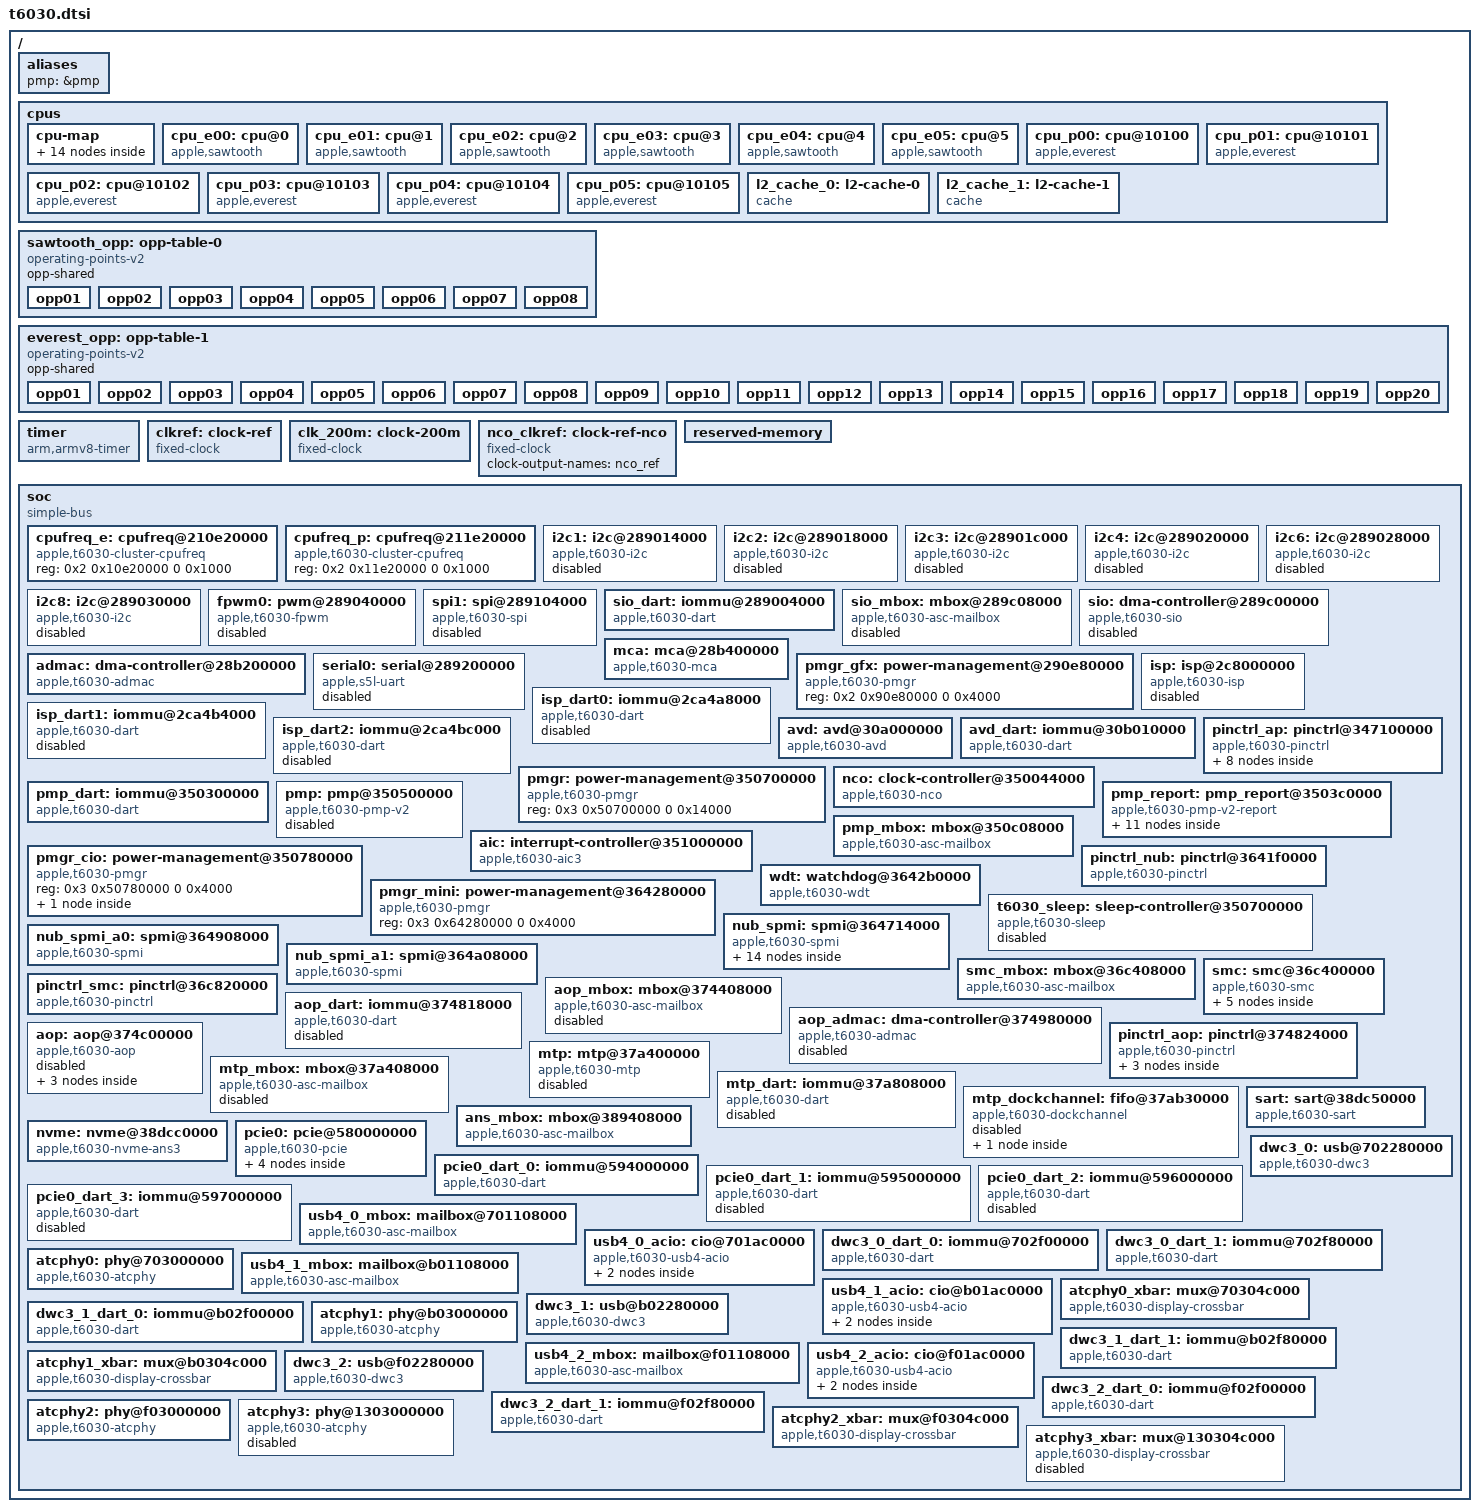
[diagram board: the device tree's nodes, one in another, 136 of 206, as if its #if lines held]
// SPDX-License-Identifier: GPL-2.0+ OR MIT
/*
 * Apple T6030 "M3 Pro" SoC
 *
 * Other names: H15J, "Lobos"
 *
 * Copyright The Asahi Linux Contributors
 */

#include <dt-bindings/gpio/gpio.h>
#include <dt-bindings/interrupt-controller/apple-aic.h>
#include <dt-bindings/interrupt-controller/irq.h>
#include <dt-bindings/pinctrl/apple.h>
#include <dt-bindings/phy/phy.h>
#include <dt-bindings/spmi/spmi.h>

/ {
	#address-cells = <2>;
	#size-cells = <2>;

	aliases {
		#ifdef APPLE_USE_PMP
		pmp = &pmp;
		#endif
	};

	cpus {
		#address-cells = <2>;
		#size-cells = <0>;

		cpu-map {
			cluster0 {
				core0 {
					cpu = <&cpu_e00>;
				};
				core1 {
					cpu = <&cpu_e01>;
				};
				core2 {
					cpu = <&cpu_e02>;
				};
				core3 {
					cpu = <&cpu_e03>;
				};
				core4 {
					cpu = <&cpu_e04>;
				};
				core5 {
					cpu = <&cpu_e05>;
				};
			};

			cluster1 {
				core0 {
					cpu = <&cpu_p00>;
				};
				core1 {
					cpu = <&cpu_p01>;
				};
				core2 {
					cpu = <&cpu_p02>;
				};
				core3 {
					cpu = <&cpu_p03>;
				};
				core4 {
					cpu = <&cpu_p04>;
				};
				core5 {
					cpu = <&cpu_p05>;
				};
			};
		};

		cpu_e00: cpu@0 {
			compatible = "apple,sawtooth";
			device_type = "cpu";
			reg = <0x0 0x0>;
			enable-method = "spin-table";
			cpu-release-addr = <0 0>; /* to be filled by loader */
			next-level-cache = <&l2_cache_0>;
			i-cache-size = <0x20000>;
			d-cache-size = <0x10000>;
			operating-points-v2 = <&sawtooth_opp>;
			capacity-dmips-mhz = <851>;
			performance-domains = <&cpufreq_e>;
		};

		cpu_e01: cpu@1 {
			compatible = "apple,sawtooth";
			device_type = "cpu";
			reg = <0x0 0x1>;
			enable-method = "spin-table";
			cpu-release-addr = <0 0>; /* to be filled by loader */
			next-level-cache = <&l2_cache_0>;
			i-cache-size = <0x20000>;
			d-cache-size = <0x10000>;
			operating-points-v2 = <&sawtooth_opp>;
			capacity-dmips-mhz = <851>;
			performance-domains = <&cpufreq_e>;
		};

		cpu_e02: cpu@2 {
			compatible = "apple,sawtooth";
			device_type = "cpu";
			reg = <0x0 0x2>;
			enable-method = "spin-table";
			cpu-release-addr = <0 0>; /* to be filled by loader */
			next-level-cache = <&l2_cache_0>;
			i-cache-size = <0x20000>;
			d-cache-size = <0x10000>;
			operating-points-v2 = <&sawtooth_opp>;
			capacity-dmips-mhz = <851>;
			performance-domains = <&cpufreq_e>;
		};

		cpu_e03: cpu@3 {
			compatible = "apple,sawtooth";
			device_type = "cpu";
			reg = <0x0 0x3>;
			enable-method = "spin-table";
			cpu-release-addr = <0 0>; /* to be filled by loader */
			next-level-cache = <&l2_cache_0>;
			i-cache-size = <0x20000>;
			d-cache-size = <0x10000>;
			operating-points-v2 = <&sawtooth_opp>;
			capacity-dmips-mhz = <851>;
			performance-domains = <&cpufreq_e>;
		};

		cpu_e04: cpu@4 {
			compatible = "apple,sawtooth";
			device_type = "cpu";
			reg = <0x0 0x4>;
			enable-method = "spin-table";
			cpu-release-addr = <0 0>; /* to be filled by loader */
			next-level-cache = <&l2_cache_0>;
			i-cache-size = <0x20000>;
			d-cache-size = <0x10000>;
			operating-points-v2 = <&sawtooth_opp>;
			capacity-dmips-mhz = <851>;
			performance-domains = <&cpufreq_e>;
		};

		cpu_e05: cpu@5 {
			compatible = "apple,sawtooth";
			device_type = "cpu";
			reg = <0x0 0x5>;
			enable-method = "spin-table";
			cpu-release-addr = <0 0>; /* to be filled by loader */
			next-level-cache = <&l2_cache_0>;
			i-cache-size = <0x20000>;
			d-cache-size = <0x10000>;
			operating-points-v2 = <&sawtooth_opp>;
			capacity-dmips-mhz = <851>;
			performance-domains = <&cpufreq_e>;
		};

		cpu_p00: cpu@10100 {
			compatible = "apple,everest";
			device_type = "cpu";
			reg = <0x0 0x10100>;
			enable-method = "spin-table";
			cpu-release-addr = <0 0>; /* To be filled by loader */
			next-level-cache = <&l2_cache_1>;
			i-cache-size = <0x30000>;
			d-cache-size = <0x20000>;
			operating-points-v2 = <&everest_opp>;
			capacity-dmips-mhz = <1024>;
			performance-domains = <&cpufreq_p>;
		};

		cpu_p01: cpu@10101 {
			compatible = "apple,everest";
			device_type = "cpu";
			reg = <0x0 0x10101>;
			enable-method = "spin-table";
			cpu-release-addr = <0 0>; /* To be filled by loader */
			next-level-cache = <&l2_cache_1>;
			i-cache-size = <0x30000>;
			d-cache-size = <0x20000>;
			operating-points-v2 = <&everest_opp>;
			capacity-dmips-mhz = <1024>;
			performance-domains = <&cpufreq_p>;
		};

		cpu_p02: cpu@10102 {
			compatible = "apple,everest";
			device_type = "cpu";
			reg = <0x0 0x10102>;
			enable-method = "spin-table";
			cpu-release-addr = <0 0>; /* To be filled by loader */
			next-level-cache = <&l2_cache_1>;
			i-cache-size = <0x30000>;
			d-cache-size = <0x20000>;
			operating-points-v2 = <&everest_opp>;
			capacity-dmips-mhz = <1024>;
			performance-domains = <&cpufreq_p>;
		};

		cpu_p03: cpu@10103 {
			compatible = "apple,everest";
			device_type = "cpu";
			reg = <0x0 0x10103>;
			enable-method = "spin-table";
			cpu-release-addr = <0 0>; /* To be filled by loader */
			next-level-cache = <&l2_cache_1>;
			i-cache-size = <0x30000>;
			d-cache-size = <0x20000>;
			operating-points-v2 = <&everest_opp>;
			capacity-dmips-mhz = <1024>;
			performance-domains = <&cpufreq_p>;
		};

		cpu_p04: cpu@10104 {
			compatible = "apple,everest";
			device_type = "cpu";
			reg = <0x0 0x10104>;
			enable-method = "spin-table";
			cpu-release-addr = <0 0>; /* To be filled by loader */
			next-level-cache = <&l2_cache_1>;
			i-cache-size = <0x30000>;
			d-cache-size = <0x20000>;
			operating-points-v2 = <&everest_opp>;
			capacity-dmips-mhz = <1024>;
			performance-domains = <&cpufreq_p>;
		};

		cpu_p05: cpu@10105 {
			compatible = "apple,everest";
			device_type = "cpu";
			reg = <0x0 0x10105>;
			enable-method = "spin-table";
			cpu-release-addr = <0 0>; /* To be filled by loader */
			next-level-cache = <&l2_cache_1>;
			i-cache-size = <0x30000>;
			d-cache-size = <0x20000>;
			operating-points-v2 = <&everest_opp>;
			capacity-dmips-mhz = <1024>;
			performance-domains = <&cpufreq_p>;
		};

		l2_cache_0: l2-cache-0 {
			compatible = "cache";
			cache-level = <2>;
			cache-unified;
			cache-size = <0x400000>;
		};

		l2_cache_1: l2-cache-1 {
			compatible = "cache";
			cache-level = <2>;
			cache-unified;
			cache-size = <0x1000000>;
		};
	};

	sawtooth_opp: opp-table-0 {
		compatible = "operating-points-v2";
		opp-shared;

		opp01 {
			opp-hz = /bits/ 64 <744000000>;
			opp-level = <1>;
			clock-latency-ns = <7700>;
		};
		opp02 {
			opp-hz = /bits/ 64 <1044000000>;
			opp-level = <2>;
			clock-latency-ns = <21200>;
		};
		opp03 {
			opp-hz = /bits/ 64 <1476000000>;
			opp-level = <3>;
			clock-latency-ns = <26400>;
		};
		opp04 {
			opp-hz = /bits/ 64 <2004000000>;
			opp-level = <4>;
			clock-latency-ns = <40500>;
		};
		opp05 {
			opp-hz = /bits/ 64 <2268000000>;
			opp-level = <5>;
			clock-latency-ns = <44400>;
		};
		opp06 {
			opp-hz = /bits/ 64 <2448000000>;
			opp-level = <6>;
			clock-latency-ns = <47200>;
		};
		opp07 {
			opp-hz = /bits/ 64 <2640000000>;
			opp-level = <7>;
			clock-latency-ns = <52000>;
		};
		opp08 {
			opp-hz = /bits/ 64 <2748000000>;
			opp-level = <8>;
			clock-latency-ns = <52000>;
		};
	};

	everest_opp: opp-table-1 {
		compatible = "operating-points-v2";
		opp-shared;

		opp01 {
			opp-hz = /bits/ 64 <696000000>;
			opp-level = <1>;
			clock-latency-ns = <8600>;
		};
		opp02 {
			opp-hz = /bits/ 64 <1092000000>;
			opp-level = <2>;
			clock-latency-ns = <18700>;
		};
		opp03 {
			opp-hz = /bits/ 64 <1356000000>;
			opp-level = <3>;
			clock-latency-ns = <20700>;
		};
		opp04 {
			opp-hz = /bits/ 64 <1596000000>;
			opp-level = <4>;
			clock-latency-ns = <24800>;
		};
		opp05 {
			opp-hz = /bits/ 64 <1884000000>;
			opp-level = <5>;
			clock-latency-ns = <30700>;
		};
		opp06 {
			opp-hz = /bits/ 64 <2172000000>;
			opp-level = <6>;
			clock-latency-ns = <34400>;
		};
		opp07 {
			opp-hz = /bits/ 64 <2424000000>;
			opp-level = <7>;
			clock-latency-ns = <39600>;
		};
		opp08 {
			opp-hz = /bits/ 64 <2616000000>;
			opp-level = <8>;
			clock-latency-ns = <40000>;
		};
		opp09 {
			opp-hz = /bits/ 64 <2808000000>;
			opp-level = <9>;
			clock-latency-ns = <41800>;
		};
		opp10 {
			opp-hz = /bits/ 64 <2988000000>;
			opp-level = <10>;
			clock-latency-ns = <45300>;
		};
		opp11 {
			opp-hz = /bits/ 64 <3144000000>;
			opp-level = <11>;
			clock-latency-ns = <46700>;
		};
		opp12 {
			opp-hz = /bits/ 64 <3288000000>;
			opp-level = <12>;
			clock-latency-ns = <49200>;
		};
		opp13 {
			opp-hz = /bits/ 64 <3420000000>;
			opp-level = <13>;
			clock-latency-ns = <53900>;
		};
		opp14 {
			opp-hz = /bits/ 64 <3576000000>;
			opp-level = <14>;
			clock-latency-ns = <53700>;
		};
		opp15 {
			opp-hz = /bits/ 64 <3624000000>;
			opp-level = <15>;
			clock-latency-ns = <54000>;
		};
		opp16 {
			opp-hz = /bits/ 64 <3708000000>;
			opp-level = <16>;
			clock-latency-ns = <54000>;
		};
		opp17 {
			opp-hz = /bits/ 64 <3780000000>;
			opp-level = <17>;
			clock-latency-ns = <54100>;
		};
		opp18 {
			opp-hz = /bits/ 64 <3864000000>;
			opp-level = <18>;
			clock-latency-ns = <54300>;
		};
		opp19 {
			opp-hz = /bits/ 64 <3960000000>;
			opp-level = <19>;
			clock-latency-ns = <58400>;
		};
		opp20 {
			opp-hz = /bits/ 64 <4056000000>;
			opp-level = <20>;
			clock-latency-ns = <58700>;
		};
	};

	timer {
		compatible = "arm,armv8-timer";
		interrupt-parent = <&aic>;
		interrupt-names = "phys", "virt", "hyp-phys", "hyp-virt";
		interrupts = <AIC_FIQ AIC_TMR_GUEST_PHYS IRQ_TYPE_LEVEL_HIGH>,
			     <AIC_FIQ AIC_TMR_GUEST_VIRT IRQ_TYPE_LEVEL_HIGH>,
			     <AIC_FIQ AIC_TMR_HV_PHYS IRQ_TYPE_LEVEL_HIGH>,
			     <AIC_FIQ AIC_TMR_HV_VIRT IRQ_TYPE_LEVEL_HIGH>;
	};

	clkref: clock-ref {
		compatible = "fixed-clock";
		#clock-cells = <0>;
		clock-frequency = <24000000>;
		clock-output-names = "clkref";
	};

	clk_200m: clock-200m {
		compatible = "fixed-clock";
		#clock-cells = <0>;
		clock-frequency = <200000000>;
		clock-output-names = "clk_200m";
	};

	/*
	 * This is a fabulated representation of the input clock
	 * to NCO since we don't know the true clock tree.
	 */
	nco_clkref: clock-ref-nco {
		compatible = "fixed-clock";
		#clock-cells = <0>;
		clock-output-names = "nco_ref";
	};

	reserved-memory {
		#address-cells = <2>;
		#size-cells = <2>;
		ranges;
	};

	soc: soc {
		compatible = "simple-bus";
		#address-cells = <2>;
		#size-cells = <2>;

		ranges;
		nonposted-mmio;
		/* Required to get >32-bit DMA via DARTs */
		dma-ranges = <0 0 0 0 0xffffffff 0xffffc000>;

		cpufreq_e: cpufreq@210e20000 {
			compatible = "apple,t6030-cluster-cpufreq", "apple,t8112-cluster-cpufreq";
			reg = <0x2 0x10e20000 0 0x1000>;
			#performance-domain-cells = <0>;
		};

		cpufreq_p: cpufreq@211e20000 {
			compatible = "apple,t6030-cluster-cpufreq", "apple,t8112-cluster-cpufreq";
			reg = <0x2 0x11e20000 0 0x1000>;
			#performance-domain-cells = <0>;
		};

		i2c1: i2c@289014000 {
			compatible = "apple,t6030-i2c", "apple,t8103-i2c";
			reg = <0x2 0x89014000 0x0 0x4000>;
			clocks = <&clkref>;
			interrupt-parent = <&aic>;
			interrupts = <AIC_IRQ 890 IRQ_TYPE_LEVEL_HIGH>;
			pinctrl-0 = <&i2c1_pins>;
			pinctrl-names = "default";
			#address-cells = <0x1>;
			#size-cells = <0x0>;
			power-domains = <&ps_i2c1>;
			status = "disabled";
		};

		i2c2: i2c@289018000 {
			compatible = "apple,t6030-i2c", "apple,t8103-i2c";
			reg = <0x2 0x89018000 0x0 0x4000>;
			clocks = <&clkref>;
			interrupt-parent = <&aic>;
			interrupts = <AIC_IRQ 891 IRQ_TYPE_LEVEL_HIGH>;
			pinctrl-0 = <&i2c2_pins>;
			pinctrl-names = "default";
			#address-cells = <0x1>;
			#size-cells = <0x0>;
			power-domains = <&ps_i2c2>;
			status = "disabled";
		};

		i2c3: i2c@28901c000 {
			compatible = "apple,t6030-i2c", "apple,t8103-i2c";
			reg = <0x2 0x8901c000 0x0 0x4000>;
			clocks = <&clkref>;
			interrupt-parent = <&aic>;
			interrupts = <AIC_IRQ 892 IRQ_TYPE_LEVEL_HIGH>;
			pinctrl-0 = <&i2c3_pins>;
			pinctrl-names = "default";
			#address-cells = <0x1>;
			#size-cells = <0x0>;
			power-domains = <&ps_i2c3>;
			status = "disabled";
		};

		i2c4: i2c@289020000 {
			compatible = "apple,t6030-i2c", "apple,t8103-i2c";
			reg = <0x2 0x89020000 0x0 0x4000>;
			clocks = <&clkref>;
			interrupt-parent = <&aic>;
			interrupts = <AIC_IRQ 893 IRQ_TYPE_LEVEL_HIGH>;
			pinctrl-0 = <&i2c4_pins>;
			pinctrl-names = "default";
			#address-cells = <0x1>;
			#size-cells = <0x0>;
			power-domains = <&ps_i2c4>;
			status = "disabled";
		};

		i2c6: i2c@289028000 {
			compatible = "apple,t6030-i2c", "apple,t8103-i2c";
			reg = <0x2 0x89028000 0x0 0x4000>;
			clocks = <&clkref>;
			interrupt-parent = <&aic>;
			interrupts = <AIC_IRQ 895 IRQ_TYPE_LEVEL_HIGH>;
			pinctrl-0 = <&i2c6_pins>;
			pinctrl-names = "default";
			#address-cells = <0x1>;
			#size-cells = <0x0>;
			power-domains = <&ps_i2c6>;
			status = "disabled";
		};

		i2c8: i2c@289030000 {
			compatible = "apple,t6030-i2c", "apple,t8103-i2c";
			reg = <0x2 0x89030000 0x0 0x4000>;
			clocks = <&clkref>;
			interrupt-parent = <&aic>;
			interrupts = <AIC_IRQ 897 IRQ_TYPE_LEVEL_HIGH>;
			pinctrl-0 = <&i2c8_pins>;
			pinctrl-names = "default";
			#address-cells = <0x1>;
			#size-cells = <0x0>;
			power-domains = <&ps_i2c8>;
			status = "disabled";
		};

		fpwm0: pwm@289040000 {
			compatible = "apple,t6030-fpwm", "apple,s5l-fpwm";
			reg = <0x2 0x89040000 0x0 0x4000>;
			power-domains = <&ps_fpwm0>;
			clocks = <&clkref>;
			#pwm-cells = <2>;
			status = "disabled";
		};

		spi1: spi@289104000 {
			compatible = "apple,t6030-spi", "apple,t8103-spi";
			reg = <0x2 0x89104000 0x0 0x4000>;
			interrupt-parent = <&aic>;
			interrupts = <AIC_IRQ 875 IRQ_TYPE_LEVEL_HIGH>;
			#address-cells = <1>;
			#size-cells = <0>;
			clocks = <&clk_200m>;
			pinctrl-0 = <&spi1_pins>;
			pinctrl-names = "default";
			power-domains = <&ps_spi1>;
			status = "disabled";
		};

		sio_dart: iommu@289004000 {
			compatible = "apple,t6030-dart", "apple,t8110-dart";
			reg = <0x2 0x89004000 0x0 0x4000>;
			interrupt-parent = <&aic>;
			interrupts = <AIC_IRQ 901 IRQ_TYPE_LEVEL_HIGH>;
			#iommu-cells = <1>;
			power-domains = <&ps_sio>;
		};

		sio_mbox: mbox@289c08000 {
			compatible = "apple,t6030-asc-mailbox", "apple,asc-mailbox-v4";
			reg = <0x2 0x89c08000 0x0 0x4000>;
			interrupt-parent = <&aic>;
			interrupts = <AIC_IRQ 907 IRQ_TYPE_LEVEL_HIGH>,
				<AIC_IRQ 908 IRQ_TYPE_LEVEL_HIGH>,
				<AIC_IRQ 909 IRQ_TYPE_LEVEL_HIGH>,
				<AIC_IRQ 910 IRQ_TYPE_LEVEL_HIGH>;
			interrupt-names = "send-empty", "send-not-empty",
				"recv-empty", "recv-not-empty";
			#mbox-cells = <0>;
			power-domains = <&ps_sio_cpu>;
			status = "disabled";
		};

		/* Enabled by the boot loader with its firmware and parameters. */
		sio: dma-controller@289c00000 {
			compatible = "apple,t6030-sio", "apple,sio";
			reg = <0x2 0x89c00000 0x0 0x8000>;
			dma-channels = <128>;
			#dma-cells = <1>;
			mboxes = <&sio_mbox>;
			iommus = <&sio_dart 0>;
			power-domains = <&ps_sio_cpu>;
			status = "disabled";
		};

		admac: dma-controller@28b200000 {
			compatible = "apple,t6030-admac", "apple,t8122-admac";
			reg = <0x2 0x8b200000 0x0 0x34000>;
			#dma-cells = <1>;
			dma-channels = <24>;
			interrupts-extended = <0>,
					      <&aic AIC_IRQ 888 IRQ_TYPE_LEVEL_HIGH>,
					      <0>,
					      <0>;
			iommus = <&sio_dart 2>;
			power-domains = <&ps_sio_adma>;
			resets = <&ps_audio_p>;
		};

		mca: mca@28b400000 {
			compatible = "apple,t6030-mca", "apple,t8103-mca";
			reg = <0x2 0x8b400000 0x0 0x10000>,
			      <0x2 0x8b300000 0x0 0x20000>;
			clocks = <&nco 0>, <&nco 1>, <&nco 2>, <&nco 3>;
			dmas = <&admac 0>, <&admac 1>, <&admac 2>, <&admac 3>,
			       <&admac 4>, <&admac 5>, <&admac 6>, <&admac 7>,
			       <&admac 8>, <&admac 9>, <&admac 10>, <&admac 11>,
			       <&admac 12>, <&admac 13>, <&admac 14>, <&admac 15>;
			dma-names = "tx0a", "rx0a", "tx0b", "rx0b",
				    "tx1a", "rx1a", "tx1b", "rx1b",
				    "tx2a", "rx2a", "tx2b", "rx2b",
				    "tx3a", "rx3a", "tx3b", "rx3b";
			interrupt-parent = <&aic>;
			interrupts = <AIC_IRQ 881 IRQ_TYPE_LEVEL_HIGH>,
				     <AIC_IRQ 882 IRQ_TYPE_LEVEL_HIGH>,
				     <AIC_IRQ 883 IRQ_TYPE_LEVEL_HIGH>,
				     <AIC_IRQ 884 IRQ_TYPE_LEVEL_HIGH>;
			power-domains = <&ps_audio_p>, <&ps_mca0>, <&ps_mca1>,
					<&ps_mca2>, <&ps_mca3>;
			resets = <&ps_audio_p>;
			#sound-dai-cells = <1>;
		};

		serial0: serial@289200000 {
			compatible = "apple,s5l-uart";
			reg = <0x2 0x89200000 0x0 0x1000>;
			reg-io-width = <4>;
			interrupt-parent = <&aic>;
			interrupts = <AIC_IRQ 866 IRQ_TYPE_LEVEL_HIGH>;
			/*
			 * TODO: figure out the clocking properly, there may
			 * be a third selectable clock.
			 */
			clocks = <&clkref>, <&clkref>;
			clock-names = "uart", "clk_uart_baud0";
			power-domains = <&ps_uart0>;
			status = "disabled";
		};

		pmgr_gfx: power-management@290e80000 {
			compatible = "apple,t6030-pmgr", "apple,t8103-pmgr", "syscon", "simple-mfd";
			#address-cells = <1>;
			#size-cells = <1>;

			reg = <0x2 0x90e80000 0 0x4000>;
			/* child nodes are added in t6030-pmgr.dtsi */
		};

		isp: isp@2c8000000 {
			compatible = "apple,t6030-isp";
			iommus = <&isp_dart0 0>, <&isp_dart1 0>, <&isp_dart2 0>;
			reg-names = "coproc", "mbox", "gpio", "mbox2";
			reg = <0x2 0xc8000000 0x0 0x2000000>,
				<0x2 0xca4c4000 0x0 0x100>,
				<0x2 0xca4c41d0 0x0 0x100>,
				<0x2 0xca4c4458 0x0 0x100>;
			interrupt-parent = <&aic>;
			interrupts = <AIC_IRQ 359 IRQ_TYPE_LEVEL_HIGH>;
			power-domains = <&ps_isp_sys>, <&ps_ispsens0>,
				<&ps_isp_cpu>, <&ps_isp_fe>, <&ps_dprx>,
				<&ps_isp_secure>, <&ps_isp_be>, <&ps_isp_clr>;
			apple,dart-vm-size = <0x0 0xa0000000>;

			status = "disabled";
		};

		isp_dart0: iommu@2ca4a8000 {
			compatible = "apple,t6030-dart", "apple,t8110-dart";
			reg = <0x2 0xca4a8000 0x0 0x4000>;
			#iommu-cells = <1>;
			interrupt-parent = <&aic>;
			interrupts = <AIC_IRQ 364 IRQ_TYPE_LEVEL_HIGH>;
			power-domains = <&ps_isp_sys>;
			status = "disabled";
		};

		isp_dart1: iommu@2ca4b4000 {
			compatible = "apple,t6030-dart", "apple,t8110-dart";
			reg = <0x2 0xca4b4000 0x0 0x4000>;
			#iommu-cells = <1>;
			interrupt-parent = <&aic>;
			interrupts = <AIC_IRQ 364 IRQ_TYPE_LEVEL_HIGH>;
			power-domains = <&ps_isp_sys>;
			status = "disabled";
		};

		isp_dart2: iommu@2ca4bc000 {
			compatible = "apple,t6030-dart", "apple,t8110-dart";
			reg = <0x2 0xca4bc000 0x0 0x4000>;
			#iommu-cells = <1>;
			interrupt-parent = <&aic>;
			interrupts = <AIC_IRQ 364 IRQ_TYPE_LEVEL_HIGH>;
			power-domains = <&ps_isp_sys>;
			status = "disabled";
		};

		avd: avd@30a000000 {
			compatible = "apple,t6030-avd", "apple,t8122-avd";
			interrupt-parent = <&aic>;
			interrupts = <AIC_IRQ 788 IRQ_TYPE_LEVEL_HIGH>,
				<AIC_IRQ 789 IRQ_TYPE_LEVEL_HIGH>;
			#if defined(APPLE_USE_PMP)
			power-domains = <&pmp_report_avd_sys>;
			#else
			power-domains = <&ps_avd_sys>;
			#endif
			resets = <&ps_avd_sys>;
			reg = <0x3 0x0b080000 0x0 0x12000>,
				<0x3 0x0b092000 0x0 0x12000>,
				<0x3 0x0b0a4000 0x0 0x4000>,
				<0x3 0x0b100000 0x0 0x10000>;
			reg-names = "code", "sram", "mbox", "ctrl";
			iommus = <&avd_dart 0>;
		};

		avd_dart: iommu@30b010000 {
			compatible = "apple,t6030-dart", "apple,t8110-dart";
			reg = <0x3 0x0b010000 0x0 0x4000>;
			#iommu-cells = <1>;
			interrupt-parent = <&aic>;
			interrupts = <AIC_IRQ 795 IRQ_TYPE_LEVEL_HIGH>;
			power-domains = <&ps_avd_sys>;
		};

		pinctrl_ap: pinctrl@347100000 {
			compatible = "apple,t6030-pinctrl", "apple,t8103-pinctrl";
			reg = <0x3 0x47100000 0x0 0x4000>;

			interrupt-parent = <&aic>;
			interrupts = <AIC_IRQ 273 IRQ_TYPE_LEVEL_HIGH>,
				     <AIC_IRQ 274 IRQ_TYPE_LEVEL_HIGH>,
				     <AIC_IRQ 275 IRQ_TYPE_LEVEL_HIGH>,
				     <AIC_IRQ 276 IRQ_TYPE_LEVEL_HIGH>,
				     <AIC_IRQ 277 IRQ_TYPE_LEVEL_HIGH>,
				     <AIC_IRQ 278 IRQ_TYPE_LEVEL_HIGH>,
				     <AIC_IRQ 279 IRQ_TYPE_LEVEL_HIGH>;

			power-domains = <&ps_gpio>;

			gpio-controller;
			#gpio-cells = <2>;
			gpio-ranges = <&pinctrl_ap 0 0 224>;
			apple,npins = <224>;

			interrupt-controller;
			#interrupt-cells = <2>;

			i2c1_pins: i2c1-pins {
				pinmux = <APPLE_PINMUX(37, 1)>,
					 <APPLE_PINMUX(36, 1)>;
			};

			i2c2_pins: i2c2-pins {
				pinmux = <APPLE_PINMUX(43, 1)>,
					 <APPLE_PINMUX(42, 1)>;
			};

			i2c3_pins: i2c3-pins {
				pinmux = <APPLE_PINMUX(41, 1)>,
					 <APPLE_PINMUX(40, 1)>;
			};

			i2c4_pins: i2c4-pins {
				pinmux = <APPLE_PINMUX(39, 1)>,
					 <APPLE_PINMUX(38, 1)>;
			};

			i2c6_pins: i2c6-pins {
				pinmux = <APPLE_PINMUX(47, 1)>,
					 <APPLE_PINMUX(46, 1)>;
			};

			i2c8_pins: i2c8-pins {
				pinmux = <APPLE_PINMUX(51, 1)>,
					 <APPLE_PINMUX(50, 1)>;
			};

			spi1_pins: spi1-pins {
				pinmux = <APPLE_PINMUX(24, 1)>, /* SDI */
					<APPLE_PINMUX(25, 1)>,  /* SDO */
					<APPLE_PINMUX(26, 1)>,  /* SCK */
					<APPLE_PINMUX(27, 1)>;  /* CS */
			};

			pcie_pins: pcie-pins {
				// clkreq pins
				pinmux = <APPLE_PINMUX(163, 1)>,
					 <APPLE_PINMUX(164, 1)>,
					 <APPLE_PINMUX(165, 1)>,
					 <APPLE_PINMUX(166, 1)>;
			};
		};

		pmgr: power-management@350700000 {
			compatible = "apple,t6030-pmgr", "apple,t8103-pmgr", "syscon", "simple-mfd";
			#address-cells = <1>;
			#size-cells = <1>;

			reg = <0x3 0x50700000 0 0x14000>;
			/* child nodes are added in t6030-pmgr.dtsi */
		};

		nco: clock-controller@350044000 {
			compatible = "apple,t6030-nco", "apple,t8103-nco";
			reg = <0x3 0x50044000 0x0 0x14000>;
			clocks = <&nco_clkref>;
			#clock-cells = <1>;
		};

		/* The display handoff gate installs PMP unless explicitly static. */
		#ifdef APPLE_USE_PMP
		pmp_dart: iommu@350300000 {
			compatible = "apple,t6030-dart", "apple,t8110-dart";
			reg = <0x3 0x50300000 0x0 0x4000>;
			#iommu-cells = <1>;
			interrupt-parent = <&aic>;
			interrupts = <AIC_IRQ 734 IRQ_TYPE_LEVEL_HIGH>;
			power-domains = <&ps_pmp>;
		};

		pmp_report: pmp_report@3503c0000 {
			compatible = "apple,t6030-pmp-v2-report";
			reg = <0x3 0x503c0000 0x0 0x20000>;
			power-domains = <&ps_pms_sram>;
			#address-cells = <1>;
			#size-cells = <0>;

			pmp_report_ane_sys: report@5 {
				compatible = "apple,t6030-pmp-v2-report-entry",
					     "apple,t6000-pmp-v2-report-entry";
				reg = <0x5>;
				label = "pmp-ane-sys";
				#power-domain-cells = <0>;
				power-domains = <&ps_ane_sys>;
				status = "disabled";
			};

			pmp_report_isp_sys: report@6 {
				compatible = "apple,t6030-pmp-v2-report-entry",
					     "apple,t6000-pmp-v2-report-entry";
				reg = <0x6>;
				label = "pmp-isp-sys";
				#power-domain-cells = <0>;
				power-domains = <&ps_isp_sys>;
				status = "disabled";
			};

			pmp_report_disp: report@7 {
				compatible = "apple,t6030-pmp-v2-report-entry",
					     "apple,t6000-pmp-v2-report-entry";
				reg = <0x7>;
				label = "pmp-disp";
				#power-domain-cells = <0>;
				power-domains = <&ps_disp_cpu>;
				apple,always-on;
			};

			pmp_report_dispext0: report@8 {
				compatible = "apple,t6030-pmp-v2-report-entry",
					     "apple,t6000-pmp-v2-report-entry";
				reg = <0x8>;
				label = "pmp-dispext0";
				#power-domain-cells = <0>;
				power-domains = <&ps_dispext0_cpu>;
			};

			pmp_report_dispext1: report@9 {
				compatible = "apple,t6030-pmp-v2-report-entry",
					     "apple,t6000-pmp-v2-report-entry";
				reg = <0x9>;
				label = "pmp-dispext1";
				#power-domain-cells = <0>;
				power-domains = <&ps_dispext1_cpu>;
			};

			pmp_report_venc_sys: report@a {
				compatible = "apple,t6030-pmp-v2-report-entry",
					     "apple,t6000-pmp-v2-report-entry";
				reg = <0xa>;
				label = "pmp-venc-sys";
				#power-domain-cells = <0>;
				power-domains = <&ps_venc_sys>;
				status = "disabled";
			};

			pmp_report_avd_sys: report@b {
				compatible = "apple,t6030-pmp-v2-report-entry",
					     "apple,t6000-pmp-v2-report-entry";
				reg = <0xb>;
				label = "pmp-avd-sys";
				#power-domain-cells = <0>;
				power-domains = <&ps_avd_sys>;
			};

			pmp_report_msr: report@c {
				compatible = "apple,t6030-pmp-v2-report-entry",
					     "apple,t6000-pmp-v2-report-entry";
				reg = <0xc>;
				label = "pmp-msr";
				#power-domain-cells = <0>;
				power-domains = <&ps_msr>;
				status = "disabled";
			};

			pmp_report_jpg: report@d {
				compatible = "apple,t6030-pmp-v2-report-entry",
					     "apple,t6000-pmp-v2-report-entry";
				reg = <0xd>;
				label = "pmp-jpg";
				#power-domain-cells = <0>;
				power-domains = <&ps_jpg>;
				status = "disabled";
			};

			pmp_report_scodec: report@e {
				compatible = "apple,t6030-pmp-v2-report-entry",
					     "apple,t6000-pmp-v2-report-entry";
				reg = <0xe>;
				label = "pmp-scodec";
				#power-domain-cells = <0>;
				power-domains = <&ps_scodec>;
				status = "disabled";
			};

			pmp_report_ans: report@10 {
				compatible = "apple,t6030-pmp-v2-report-entry",
					     "apple,t6000-pmp-v2-report-entry";
				reg = <0x10>;
				label = "pmp-ans";
				#power-domain-cells = <0>;
				power-domains = <&ps_ans>;
			};
		};

		pmp: pmp@350500000 {
			compatible = "apple,t6030-pmp-v2", "apple,t6000-pmp-v2";
			reg = <0x3 0x50500000 0x0 0x80000>,
			      <0x3 0x50c00000 0x0 0x4000>;
			reg-names = "pmp", "asc";
			mboxes = <&pmp_mbox>;
			mbox-names = "mbox";
			iommus = <&pmp_dart 0>;
			power-domains = <&ps_pmp>;
			status = "disabled";
		};

		pmp_mbox: mbox@350c08000 {
			compatible = "apple,t6030-asc-mailbox", "apple,asc-mailbox-v4";
			reg = <0x3 0x50c08000 0x0 0x4000>;
			interrupt-parent = <&aic>;
			interrupts = <AIC_IRQ 730 IRQ_TYPE_LEVEL_HIGH>,
			             <AIC_IRQ 731 IRQ_TYPE_LEVEL_HIGH>,
			             <AIC_IRQ 732 IRQ_TYPE_LEVEL_HIGH>,
			             <AIC_IRQ 733 IRQ_TYPE_LEVEL_HIGH>;
			interrupt-names = "send-empty", "send-not-empty",
			                  "recv-empty", "recv-not-empty";
			#mbox-cells = <0>;
			power-domains = <&ps_pmp>, <&ps_pms_sram>;
		};

		#endif /* APPLE_USE_PMP */

		aic: interrupt-controller@351000000 {
			compatible = "apple,t6030-aic3", "apple,t8122-aic3";
			#interrupt-cells = <3>;
			interrupt-controller;

			reg = <0x3 0x51000000 0x0 0x184000>,
			      <0x3 0x51040000 0x0 0x4000>;
			reg-names = "core", "event";
			power-domains = <&ps_aic>;
		};

		pmgr_cio: power-management@350780000 {
			compatible = "apple,t6030-pmgr", "apple,t8103-pmgr", "syscon", "simple-mfd";
			#address-cells = <1>;
			#size-cells = <1>;

			reg = <0x3 0x50780000 0 0x4000>;

			cio_reset: reset-controller@8 {
				compatible = "apple,t6030-cio-reset", "apple,t6000-cio-reset";
				reg = <0x8 0x4>;
				#reset-cells = <1>;
			};
		};

		pinctrl_nub: pinctrl@3641f0000 {
			compatible = "apple,t6030-pinctrl", "apple,t8103-pinctrl";
			reg = <0x3 0x641f0000 0x0 0x4000>;

			interrupt-parent = <&aic>;
			interrupts = <AIC_IRQ 472 IRQ_TYPE_LEVEL_HIGH>,
				     <AIC_IRQ 473 IRQ_TYPE_LEVEL_HIGH>,
				     <AIC_IRQ 474 IRQ_TYPE_LEVEL_HIGH>,
				     <AIC_IRQ 475 IRQ_TYPE_LEVEL_HIGH>,
				     <AIC_IRQ 476 IRQ_TYPE_LEVEL_HIGH>,
				     <AIC_IRQ 477 IRQ_TYPE_LEVEL_HIGH>,
				     <AIC_IRQ 478 IRQ_TYPE_LEVEL_HIGH>;

			gpio-controller;
			#gpio-cells = <2>;
			gpio-ranges = <&pinctrl_nub 0 0 37>;
			apple,npins = <37>;

			interrupt-controller;
			#interrupt-cells = <2>;
		};

		pmgr_mini: power-management@364280000 {
			compatible = "apple,t6030-pmgr", "apple,t8103-pmgr", "syscon", "simple-mfd";
			#address-cells = <1>;
			#size-cells = <1>;

			reg = <0x3 0x64280000 0 0x4000>;
			/* child nodes are added in t6030-pmgr.dtsi */
		};

		wdt: watchdog@3642b0000 {
			compatible = "apple,t6030-wdt", "apple,t8103-wdt";
			reg = <0x3 0x642b0000 0x0 0x4000>;
			clocks = <&clkref>;
			interrupt-parent = <&aic>;
			interrupts = <AIC_IRQ 480 IRQ_TYPE_LEVEL_HIGH>;
		};

		/*
		 * The blocks macOS 27.2 writes in the last 26 ms of its suspend-to-RAM,
		 * as traced on J516s under aura's hypervisor: the PMGR's power words,
		 * power gates, cores' start block, CLLT and cluster words, the clock
		 * muxes and perf word, the commit word, the watchdog, the wake block,
		 * both SPMI buses, the GPU's PMGR, the AMCCs, a DCS channel and the
		 * PTD. Shared with their drivers. Its profile is untested, so it stays
		 * disabled here.
		 */
		t6030_sleep: sleep-controller@350700000 {
			compatible = "apple,t6030-sleep";
			reg = <0x3 0x50700000 0x0 0x18000>,
			      <0x3 0x50724000 0x0 0x4000>,
			      <0x3 0x50734000 0x0 0x10>,
			      <0x3 0x50768000 0x0 0x40>,
			      <0x3 0x50780000 0x0 0x8>,
			      <0x3 0x642d4000 0x0 0x4>,
			      <0x3 0x642b0000 0x0 0x30>,
			      <0x3 0x64004000 0x0 0x48>,
			      <0x3 0x64714000 0x0 0x100>,
			      <0x3 0x64280000 0x0 0x4000>,
			      <0x3 0x64908000 0x0 0x100>,
			      <0x3 0x50040000 0x0 0x60>,
			      <0x3 0x5005c000 0x0 0x4>,
			      <0x2 0x90e80000 0x0 0x18000>,
			      <0x2 0x20000000 0x0 0xc0000>,
			      <0x2 0x22000000 0x0 0xc0000>,
			      <0x2 0x20400000 0x0 0x4000>,
			      <0x3 0x503c0000 0x0 0x20000>;
			reg-names = "ps", "pwrgate", "cpu-start", "cllt", "cluster",
				    "commit", "wdt", "wake", "spmi", "ps-aon", "spmi-a0",
				    "clk-mux", "clk-perf", "ps-gpu", "amcc0", "amcc1",
				    "dcs0", "ptd";
			apple,display-coprocessors = <&dcp>, <&dcpext>, <&dcpext1>;
			apple,pcie-host = <&pcie0>;
			/* The ADT's pmgr ap-wake-sources */
			apple,wake-enable = <3 51 74 83 87 88 89 90 91 92 93 94 104 111
					     113 132 133 147 159 169 185 190 214>;
			/*
			 * The SMC's pmVC, then the least spacings in us, as macOS's on
			 * J516s: slpw to pmVC, pmVC to slpa, slpa to the AP idle, the idle
			 * to the commit. pmVC to slpa is the shortest of macOS 27.2's three
			 * full records (4119.5, 4435.3 and 4452.1 ms; the SMC hears nothing
			 * else in between). The wake isn't traced: 0.
			 */
			apple,smc-sleep-policy = <0x100 286300 4119000 560 9510 0>;
			/*
			 * macOS 27.2's sequences on J516s, as traced, access for access, on the
			 * reg entries above by index: the PTD's no-demand votes (64-bit), and
			 * before the commit WD0, the AMCCs' ways and planes (64-bit), the DCS,
			 * the GPU's PMGR, the CPU power gates, the perf word, AFR, the cluster
			 * words, SIO, the clock muxes and CLLT.
			 */
			apple,seq-prepare =
				<8 17 0x10900 0x20000000>,
				<8 17 0x10900 0x20000000>,
				<8 17 0x10908 0x20000000>,
				<8 17 0x10918 0x20000000>,
				<8 17 0x10900 0x20000000>,
				<8 17 0x10908 0x20000000>,
				<8 17 0x10918 0x20000000>,
				<0 17 0x18328 0x20000>;
			apple,seq-notice =
				<8 17 0x10900 0x20000000>,
				<8 17 0x10908 0x20000000>,
				<8 17 0x10918 0x20000000>;
			apple,seq-commit =
				/* WD0 off */
				<0 6 0xc 0x0>,
				/* AMCC0's planes' ways, a bit at a time, in 64-bit accesses */
				<9 14 0x24000 0x1>,
				<9 14 0x24000 0x2>,
				<9 14 0x24000 0x4>,
				<9 14 0x24000 0x8>,
				<9 14 0x24000 0x10>,
				<9 14 0x24000 0x20>,
				<9 14 0x24000 0x40>,
				<9 14 0x24000 0x80>,
				<9 14 0x24000 0x100>,
				<9 14 0x24000 0x200>,
				<9 14 0x24000 0x400>,
				<9 14 0x24000 0x800>,
				<9 14 0x24000 0x1000>,
				<9 14 0x24000 0x2000>,
				<9 14 0x24000 0x4000>,
				<9 14 0x24000 0x8000>,
				<9 14 0x64000 0x1>,
				<9 14 0x64000 0x2>,
				<9 14 0x64000 0x4>,
				<9 14 0x64000 0x8>,
				<9 14 0x64000 0x10>,
				<9 14 0x64000 0x20>,
				<9 14 0x64000 0x40>,
				<9 14 0x64000 0x80>,
				<9 14 0x64000 0x100>,
				<9 14 0x64000 0x200>,
				<9 14 0x64000 0x400>,
				<9 14 0x64000 0x800>,
				<9 14 0x64000 0x1000>,
				<9 14 0x64000 0x2000>,
				<9 14 0x64000 0x4000>,
				<9 14 0x64000 0x8000>,
				<9 14 0xa4000 0x1>,
				<9 14 0xa4000 0x2>,
				<9 14 0xa4000 0x4>,
				<9 14 0xa4000 0x8>,
				<9 14 0xa4000 0x10>,
				<9 14 0xa4000 0x20>,
				<9 14 0xa4000 0x40>,
				<9 14 0xa4000 0x80>,
				<9 14 0xa4000 0x100>,
				<9 14 0xa4000 0x200>,
				<9 14 0xa4000 0x400>,
				<9 14 0xa4000 0x800>,
				<9 14 0xa4000 0x1000>,
				<9 14 0xa4000 0x2000>,
				/* Each AMCC's planes' stage words, 3 to 2 to 0, the same way */
				<9 14 0x24800 0x1>,
				<9 14 0x24800 0x2>,
				<9 14 0x64800 0x1>,
				<9 14 0x64800 0x2>,
				<9 14 0xa4800 0x1>,
				<9 14 0xa4800 0x2>,
				<9 15 0x24800 0x1>,
				<9 15 0x24800 0x2>,
				<9 15 0x64800 0x1>,
				<9 15 0x64800 0x2>,
				<9 15 0xa4800 0x1>,
				<9 15 0xa4800 0x2>,
				<3 16 0x584 0x1>,
				<3 16 0x584 0x2>,
				<3 16 0x584 0x4>,
				<3 16 0x584 0x8>,
				<3 16 0x584 0x10>,
				<3 16 0x584 0x20>,
				<3 16 0x584 0x40>,
				<3 16 0x584 0x80>,
				<3 16 0x584 0x100>,
				<3 16 0x588 0x1>,
				<3 16 0x588 0x10>,
				<3 13 0x10000 0x1>,
				<0 1 0xc0 0x80000000>,
				<0 1 0xc8 0x80000000>,
				<0 1 0xc0 0x80000000>,
				<0 1 0xc8 0x80000000>,
				<0 13 0x15000 0x0>,
				<1 13 0x153e0 0x0>,
				<0 13 0x14000 0x0>,
				<1 13 0x143e0 0x0>,
				<0 13 0x14400 0x0>,
				<1 13 0x147e0 0x0>,
				<0 13 0x14800 0x0>,
				<1 13 0x14be0 0x0>,
				<0 13 0x14c00 0x0>,
				<1 13 0x14fe0 0x0>,
				<4 12 0x0 0x0>,
				<0 13 0x100 0x0>,
				<0 4 0x0 0x0>,
				<0 4 0x4 0x0>,
				<3 0 0x1b8 0x10000000>,
				<3 0 0x1d0 0x10000000>,
				<0 11 0x48 0x80100000>,
				<0 11 0x50 0x80100000>,
				<0 11 0x4c 0x80100000>,
				<0 11 0x40 0x80100000>,
				<0 11 0x3c 0x80100000>,
				<3 3 0x24 0x30000>;
			/*
			 * macOS 27.2's wake on J516s, as aura's wake record has it: each complex's
			 * word, waited on, and two CPU power gates; after the power words, the
			 * other two gates, then the AMCCs' ways and planes and the DCS back, the
			 * reverse of apple,seq-commit's. Kinds 14 and 15 run the entries after
			 * them only for a bit that was on when read before the commit, and kinds
			 * 12 and 13 write back the words read then: Linux gets back what it had,
			 * nothing more.
			 */
			apple,seq-wake-early =
				/* Each complex on, waited on and read again, as macOS does */
				<1 4 0x0 0>, <0 4 0x0 0xf>, <6 4 0x0 0x10>, <1 4 0x0 0>,
				<1 4 0x4 0>, <0 4 0x4 0xf>, <6 4 0x4 0x10>, <1 4 0x4 0>,
				<2 1 0x0 0x80000000>, <2 1 0x60 0x80000000>;
			apple,seq-wake =
				<2 1 0xc0 0x80000000>, <2 1 0xc8 0x80000000>,
				/* AMCC0's ways that were on, a bit at a time, after their words */
				<0x4000f 14 0x24000 0x1>,
				<13 14 0x24010 0>, <13 14 0x24018 0>,
				<11 14 0x25000 0>, <10 14 0x24000 0x1>,
				<0x4000f 14 0x24000 0x2>,
				<13 14 0x24020 0>, <13 14 0x24028 0>,
				<11 14 0x25008 0>, <10 14 0x24000 0x2>,
				<0x4000f 14 0x24000 0x4>,
				<13 14 0x24030 0>, <13 14 0x24038 0>,
				<11 14 0x25010 0>, <10 14 0x24000 0x4>,
				<0x4000f 14 0x24000 0x8>,
				<13 14 0x24040 0>, <13 14 0x24048 0>,
				<11 14 0x25018 0>, <10 14 0x24000 0x8>,
				<0x4000f 14 0x24000 0x10>,
				<13 14 0x24050 0>, <13 14 0x24058 0>,
				<11 14 0x25020 0>, <10 14 0x24000 0x10>,
				<0x4000f 14 0x24000 0x20>,
				<13 14 0x24060 0>, <13 14 0x24068 0>,
				<11 14 0x25028 0>, <10 14 0x24000 0x20>,
				<0x4000f 14 0x24000 0x40>,
				<13 14 0x24070 0>, <13 14 0x24078 0>,
				<11 14 0x25030 0>, <10 14 0x24000 0x40>,
				<0x4000f 14 0x24000 0x80>,
				<13 14 0x24080 0>, <13 14 0x24088 0>,
				<11 14 0x25038 0>, <10 14 0x24000 0x80>,
				<0x4000f 14 0x24000 0x100>,
				<13 14 0x24090 0>, <13 14 0x24098 0>,
				<11 14 0x25040 0>, <10 14 0x24000 0x100>,
				<0x4000f 14 0x24000 0x200>,
				<13 14 0x240a0 0>, <13 14 0x240a8 0>,
				<11 14 0x25048 0>, <10 14 0x24000 0x200>,
				<0x4000f 14 0x24000 0x400>,
				<13 14 0x240b0 0>, <13 14 0x240b8 0>,
				<11 14 0x25050 0>, <10 14 0x24000 0x400>,
				<0x4000f 14 0x24000 0x800>,
				<13 14 0x240c0 0>, <13 14 0x240c8 0>,
				<11 14 0x25058 0>, <10 14 0x24000 0x800>,
				<0x4000f 14 0x24000 0x1000>,
				<13 14 0x240d0 0>, <13 14 0x240d8 0>,
				<11 14 0x25060 0>, <10 14 0x24000 0x1000>,
				<0x4000f 14 0x24000 0x2000>,
				<13 14 0x240e0 0>, <13 14 0x240e8 0>,
				<11 14 0x25068 0>, <10 14 0x24000 0x2000>,
				<0x4000f 14 0x24000 0x4000>,
				<13 14 0x240f0 0>, <13 14 0x240f8 0>,
				<11 14 0x25070 0>, <10 14 0x24000 0x4000>,
				<0x4000f 14 0x24000 0x8000>,
				<13 14 0x24100 0>, <13 14 0x24108 0>,
				<11 14 0x25078 0>, <10 14 0x24000 0x8000>,
				<0x4000f 14 0x64000 0x1>,
				<13 14 0x64010 0>, <13 14 0x64018 0>,
				<11 14 0x65000 0>, <10 14 0x64000 0x1>,
				<0x4000f 14 0x64000 0x2>,
				<13 14 0x64020 0>, <13 14 0x64028 0>,
				<11 14 0x65008 0>, <10 14 0x64000 0x2>,
				<0x4000f 14 0x64000 0x4>,
				<13 14 0x64030 0>, <13 14 0x64038 0>,
				<11 14 0x65010 0>, <10 14 0x64000 0x4>,
				<0x4000f 14 0x64000 0x8>,
				<13 14 0x64040 0>, <13 14 0x64048 0>,
				<11 14 0x65018 0>, <10 14 0x64000 0x8>,
				<0x4000f 14 0x64000 0x10>,
				<13 14 0x64050 0>, <13 14 0x64058 0>,
				<11 14 0x65020 0>, <10 14 0x64000 0x10>,
				<0x4000f 14 0x64000 0x20>,
				<13 14 0x64060 0>, <13 14 0x64068 0>,
				<11 14 0x65028 0>, <10 14 0x64000 0x20>,
				<0x4000f 14 0x64000 0x40>,
				<13 14 0x64070 0>, <13 14 0x64078 0>,
				<11 14 0x65030 0>, <10 14 0x64000 0x40>,
				<0x4000f 14 0x64000 0x80>,
				<13 14 0x64080 0>, <13 14 0x64088 0>,
				<11 14 0x65038 0>, <10 14 0x64000 0x80>,
				<0x4000f 14 0x64000 0x100>,
				<13 14 0x64090 0>, <13 14 0x64098 0>,
				<11 14 0x65040 0>, <10 14 0x64000 0x100>,
				<0x4000f 14 0x64000 0x200>,
				<13 14 0x640a0 0>, <13 14 0x640a8 0>,
				<11 14 0x65048 0>, <10 14 0x64000 0x200>,
				<0x4000f 14 0x64000 0x400>,
				<13 14 0x640b0 0>, <13 14 0x640b8 0>,
				<11 14 0x65050 0>, <10 14 0x64000 0x400>,
				<0x4000f 14 0x64000 0x800>,
				<13 14 0x640c0 0>, <13 14 0x640c8 0>,
				<11 14 0x65058 0>, <10 14 0x64000 0x800>,
				<0x4000f 14 0x64000 0x1000>,
				<13 14 0x640d0 0>, <13 14 0x640d8 0>,
				<11 14 0x65060 0>, <10 14 0x64000 0x1000>,
				<0x4000f 14 0x64000 0x2000>,
				<13 14 0x640e0 0>, <13 14 0x640e8 0>,
				<11 14 0x65068 0>, <10 14 0x64000 0x2000>,
				<0x4000f 14 0x64000 0x4000>,
				<13 14 0x640f0 0>, <13 14 0x640f8 0>,
				<11 14 0x65070 0>, <10 14 0x64000 0x4000>,
				<0x4000f 14 0x64000 0x8000>,
				<13 14 0x64100 0>, <13 14 0x64108 0>,
				<11 14 0x65078 0>, <10 14 0x64000 0x8000>,
				<0x4000f 14 0xa4000 0x1>,
				<13 14 0xa4010 0>, <13 14 0xa4018 0>,
				<11 14 0xa5000 0>, <10 14 0xa4000 0x1>,
				<0x4000f 14 0xa4000 0x2>,
				<13 14 0xa4020 0>, <13 14 0xa4028 0>,
				<11 14 0xa5008 0>, <10 14 0xa4000 0x2>,
				<0x4000f 14 0xa4000 0x4>,
				<13 14 0xa4030 0>, <13 14 0xa4038 0>,
				<11 14 0xa5010 0>, <10 14 0xa4000 0x4>,
				<0x4000f 14 0xa4000 0x8>,
				<13 14 0xa4040 0>, <13 14 0xa4048 0>,
				<11 14 0xa5018 0>, <10 14 0xa4000 0x8>,
				<0x4000f 14 0xa4000 0x10>,
				<13 14 0xa4050 0>, <13 14 0xa4058 0>,
				<11 14 0xa5020 0>, <10 14 0xa4000 0x10>,
				<0x4000f 14 0xa4000 0x20>,
				<13 14 0xa4060 0>, <13 14 0xa4068 0>,
				<11 14 0xa5028 0>, <10 14 0xa4000 0x20>,
				<0x4000f 14 0xa4000 0x40>,
				<13 14 0xa4070 0>, <13 14 0xa4078 0>,
				<11 14 0xa5030 0>, <10 14 0xa4000 0x40>,
				<0x4000f 14 0xa4000 0x80>,
				<13 14 0xa4080 0>, <13 14 0xa4088 0>,
				<11 14 0xa5038 0>, <10 14 0xa4000 0x80>,
				<0x4000f 14 0xa4000 0x100>,
				<13 14 0xa4090 0>, <13 14 0xa4098 0>,
				<11 14 0xa5040 0>, <10 14 0xa4000 0x100>,
				<0x4000f 14 0xa4000 0x200>,
				<13 14 0xa40a0 0>, <13 14 0xa40a8 0>,
				<11 14 0xa5048 0>, <10 14 0xa4000 0x200>,
				<0x4000f 14 0xa4000 0x400>,
				<13 14 0xa40b0 0>, <13 14 0xa40b8 0>,
				<11 14 0xa5050 0>, <10 14 0xa4000 0x400>,
				<0x4000f 14 0xa4000 0x800>,
				<13 14 0xa40c0 0>, <13 14 0xa40c8 0>,
				<11 14 0xa5058 0>, <10 14 0xa4000 0x800>,
				<0x4000f 14 0xa4000 0x1000>,
				<13 14 0xa40d0 0>, <13 14 0xa40d8 0>,
				<11 14 0xa5060 0>, <10 14 0xa4000 0x1000>,
				<0x4000f 14 0xa4000 0x2000>,
				<13 14 0xa40e0 0>, <13 14 0xa40e8 0>,
				<11 14 0xa5068 0>, <10 14 0xa4000 0x2000>,
				/* Stage bits that were on, 0 to 1 to 3, after their words */
				<0x4000f 14 0x24800 0x1>,
				<13 14 0x24858 0>, <13 14 0x24810 0>, <13 14 0x24860 0>,
				<10 14 0x24800 0x1>,
				<0x3000f 14 0x24800 0x2>,
				<13 14 0x24868 0>, <13 14 0x24870 0>,
				<10 14 0x24800 0x2>,
				<0x4000f 14 0x64800 0x1>,
				<13 14 0x64858 0>, <13 14 0x64810 0>, <13 14 0x64860 0>,
				<10 14 0x64800 0x1>,
				<0x3000f 14 0x64800 0x2>,
				<13 14 0x64868 0>, <13 14 0x64870 0>,
				<10 14 0x64800 0x2>,
				<0x4000f 14 0xa4800 0x1>,
				<13 14 0xa4858 0>, <13 14 0xa4810 0>, <13 14 0xa4860 0>,
				<10 14 0xa4800 0x1>,
				<0x3000f 14 0xa4800 0x2>,
				<13 14 0xa4868 0>, <13 14 0xa4870 0>,
				<10 14 0xa4800 0x2>,
				<0x4000f 15 0x24800 0x1>,
				<13 15 0x24858 0>, <13 15 0x24810 0>, <13 15 0x24860 0>,
				<10 15 0x24800 0x1>,
				<0x3000f 15 0x24800 0x2>,
				<13 15 0x24868 0>, <13 15 0x24870 0>,
				<10 15 0x24800 0x2>,
				<0x4000f 15 0x64800 0x1>,
				<13 15 0x64858 0>, <13 15 0x64810 0>, <13 15 0x64860 0>,
				<10 15 0x64800 0x1>,
				<0x3000f 15 0x64800 0x2>,
				<13 15 0x64868 0>, <13 15 0x64870 0>,
				<10 15 0x64800 0x2>,
				<0x4000f 15 0xa4800 0x1>,
				<13 15 0xa4858 0>, <13 15 0xa4810 0>, <13 15 0xa4860 0>,
				<10 15 0xa4800 0x1>,
				<0x3000f 15 0xa4800 0x2>,
				<13 15 0xa4868 0>, <13 15 0xa4870 0>,
				<10 15 0xa4800 0x2>,
				/* The DCS's bits that were on, one at a time, after their words */
				<0x7000e 16 0x584 0x1>,
				<12 16 0x58c 0>, <12 16 0x590 0>, <12 16 0x594 0>,
				<12 16 0x598 0>, <12 16 0x59c 0>,
				<12 16 0x580 0>, <2 16 0x584 0x1>,
				<0x7000e 16 0x584 0x2>,
				<12 16 0x5a0 0>, <12 16 0x5a4 0>, <12 16 0x5a8 0>,
				<12 16 0x5ac 0>, <12 16 0x5b0 0>,
				<12 16 0x580 0>, <2 16 0x584 0x2>,
				<0x7000e 16 0x584 0x4>,
				<12 16 0x5b4 0>, <12 16 0x5b8 0>, <12 16 0x5bc 0>,
				<12 16 0x5c0 0>, <12 16 0x5c4 0>,
				<12 16 0x580 0>, <2 16 0x584 0x4>,
				<0x7000e 16 0x584 0x8>,
				<12 16 0x5c8 0>, <12 16 0x5cc 0>, <12 16 0x5d0 0>,
				<12 16 0x5d4 0>, <12 16 0x5d8 0>,
				<12 16 0x580 0>, <2 16 0x584 0x8>,
				<0x7000e 16 0x584 0x10>,
				<12 16 0x5dc 0>, <12 16 0x5e0 0>, <12 16 0x5e4 0>,
				<12 16 0x5e8 0>, <12 16 0x5ec 0>,
				<12 16 0x580 0>, <2 16 0x584 0x10>,
				<0x7000e 16 0x584 0x20>,
				<12 16 0x5f0 0>, <12 16 0x5f4 0>, <12 16 0x5f8 0>,
				<12 16 0x5fc 0>, <12 16 0x600 0>,
				<12 16 0x580 0>, <2 16 0x584 0x20>,
				<0x7000e 16 0x584 0x40>,
				<12 16 0x604 0>, <12 16 0x608 0>, <12 16 0x60c 0>,
				<12 16 0x610 0>, <12 16 0x614 0>,
				<12 16 0x580 0>, <2 16 0x584 0x40>,
				<0x7000e 16 0x584 0x80>,
				<12 16 0x618 0>, <12 16 0x61c 0>, <12 16 0x620 0>,
				<12 16 0x624 0>, <12 16 0x628 0>,
				<12 16 0x580 0>, <2 16 0x584 0x80>,
				<0x7000e 16 0x584 0x100>,
				<12 16 0x62c 0>, <12 16 0x630 0>, <12 16 0x634 0>,
				<12 16 0x638 0>, <12 16 0x63c 0>,
				<12 16 0x580 0>, <2 16 0x584 0x100>,
				<0x2000e 16 0x588 0x1>,
				<2 16 0x588 0x100>, <2 16 0x588 0x1>,
				<0x2000e 16 0x588 0x10>,
				<2 16 0x588 0x1000>, <2 16 0x588 0x10>;
			status = "disabled";
		};

		nub_spmi: spmi@364714000 {
			compatible = "apple,t6030-spmi", "apple,t8103-spmi";
			reg = <0x3 0x64714000 0x0 0x100>;
			#address-cells = <2>;
			#size-cells = <0>;
			interrupt-parent = <&aic>;
			interrupts = <AIC_IRQ 485 IRQ_TYPE_LEVEL_HIGH>;
			interrupt-controller;
			#interrupt-cells = <2>;

			pmic1: pmic@b {
				compatible = "apple,chapel-pmic", "apple,spmi-nvmem";
				reg = <0xb SPMI_USID>;

				nvmem-layout {
					compatible = "fixed-layout";
					#address-cells = <1>;
					#size-cells = <1>;

					rtc_ctrl: rtc-ctrl@2000 {
						reg = <0x2000 0x1>;
					};

					pm_setting: pm-setting@2001 {
						reg = <0x2001 0x1>;
					};

					rtc_alarm: rtc-alarm@2008 {
						reg = <0x2008 0x4>;
					};

					rtc_alarm_mask: rtc-alarm-mask@200e {
						reg = <0x200e 0x1>;
					};

					rtc_offset: rtc-offset@2100 {
						reg = <0x2100 0x6>;
					};

					fault_shadow: fault-shadow@867b {
						reg = <0x867b 0x10>;
					};

					socd: socd@8b00 {
						reg = <0x8b00 0x400>;
					};

					boot_stage: boot-stage@f801 {
						reg = <0xf801 0x1>;
					};

					boot_error_count: boot-error-count@f802,0 {
						reg = <0xf802 0x1>;
						bits = <0 4>;
					};

					panic_count: panic-count@f802,4 {
						reg = <0xf802 0x1>;
						bits = <4 4>;
					};

					boot_error_stage: boot-error-stage@f803 {
						reg = <0xf803 0x1>;
					};

					shutdown_flag: shutdown-flag@f80f,3 {
						reg = <0xf80f 0x1>;
						bits = <3 1>;
					};
				};
			};
		};

		nub_spmi_a0: spmi@364908000 {
			compatible = "apple,t6030-spmi", "apple,t8103-spmi";
			reg = <0x3 0x64908000 0x0 0x100>;
			#address-cells = <2>;
			#size-cells = <0>;
			#interrupt-cells = <2>;
			interrupt-controller;
			interrupt-parent = <&aic>;
			interrupts = <AIC_IRQ 509 IRQ_TYPE_LEVEL_HIGH>;
			power-domains = <&ps_nub_spmi_a0>;
		};

		nub_spmi_a1: spmi@364a08000 {
			compatible = "apple,t6030-spmi", "apple,t8103-spmi";
			reg = <0x3 0x64a08000 0x0 0x100>;
			#address-cells = <2>;
			#size-cells = <0>;
			#interrupt-cells = <2>;
			interrupt-controller;
			interrupt-parent = <&aic>;
			interrupts = <AIC_IRQ 511 IRQ_TYPE_LEVEL_HIGH>;
			power-domains = <&ps_nub_spmi_a1>;
		};

		smc_mbox: mbox@36c408000 {
			compatible = "apple,t6030-asc-mailbox", "apple,asc-mailbox-v4";
			reg = <0x3 0x6c408000 0x0 0x4000>;
			interrupt-parent = <&aic>;
			interrupts = <AIC_IRQ 554 IRQ_TYPE_LEVEL_HIGH>,
				<AIC_IRQ 555 IRQ_TYPE_LEVEL_HIGH>,
				<AIC_IRQ 556 IRQ_TYPE_LEVEL_HIGH>,
				<AIC_IRQ 557 IRQ_TYPE_LEVEL_HIGH>;
			interrupt-names = "send-empty", "send-not-empty",
				"recv-empty", "recv-not-empty";
			#mbox-cells = <0>;
		};

		smc: smc@36c400000 {
			compatible = "apple,t6030-smc", "apple,t8103-smc";
			reg = <0x3 0x6c400000 0x0 0x4000>,
			      <0x3 0x6de00000 0x0 0x100000>;
			reg-names = "smc", "sram";
			mboxes = <&smc_mbox>;
			/* macOS 27.2 sets WKTP to its sleep value going to sleep on J516s. */
			apple,sleep-wake-type;

			smc_gpio: gpio@67500000 {
				compatible = "apple,smc-gpio";
				gpio-controller;
				#gpio-cells = <2>;
			};

			smc_gpio_low: gpio@67700000 {
				compatible = "apple,smc-low-gpio";
				gpio-controller;
				#gpio-cells = <2>;
			};

			smc_hwmon: hwmon {
				compatible = "apple,smc-hwmon";
			};

			smc_reboot: reboot {
				compatible = "apple,smc-reboot";
				nvmem-cells = <&shutdown_flag>, <&boot_stage>,
					<&boot_error_count>, <&panic_count>;
				nvmem-cell-names = "shutdown_flag", "boot_stage",
					"boot_error_count", "panic_count";
			};

			rtc {
				compatible = "apple,smc-rtc";
				nvmem-cells = <&rtc_offset>, <&rtc_ctrl>, <&rtc_alarm>,
					<&rtc_alarm_mask>;
				nvmem-cell-names = "rtc_offset", "rtc_ctrl", "rtc_alarm",
					"rtc_alarm_mask";
				/* The PMIC's RTC alarm, peripheral interrupt 2 of nub-spmi0 */
				interrupts-extended = <&nub_spmi 2 IRQ_TYPE_EDGE_RISING>;
				wakeup-source;
			};
		};

		pinctrl_smc: pinctrl@36c820000 {
			compatible = "apple,t6030-pinctrl", "apple,t8103-pinctrl";
			reg = <0x3 0x6c820000 0x0 0x4000>;

			gpio-controller;
			#gpio-cells = <2>;
			gpio-ranges = <&pinctrl_smc 0 0 18>;
			apple,npins = <18>;

			interrupt-controller;
			#interrupt-cells = <2>;
			interrupt-parent = <&aic>;
			interrupts = <AIC_IRQ 545 IRQ_TYPE_LEVEL_HIGH>,
				     <AIC_IRQ 546 IRQ_TYPE_LEVEL_HIGH>,
				     <AIC_IRQ 547 IRQ_TYPE_LEVEL_HIGH>,
				     <AIC_IRQ 548 IRQ_TYPE_LEVEL_HIGH>,
				     <AIC_IRQ 549 IRQ_TYPE_LEVEL_HIGH>,
				     <AIC_IRQ 550 IRQ_TYPE_LEVEL_HIGH>,
				     <AIC_IRQ 551 IRQ_TYPE_LEVEL_HIGH>;
		};

		aop_mbox: mbox@374408000 {
			compatible = "apple,t6030-asc-mailbox", "apple,asc-mailbox-v4";
			reg = <0x3 0x74408000 0x0 0x4000>;
			interrupt-parent = <&aic>;
			interrupts = <AIC_IRQ 419 IRQ_TYPE_LEVEL_HIGH>,
				<AIC_IRQ 420 IRQ_TYPE_LEVEL_HIGH>,
				<AIC_IRQ 421 IRQ_TYPE_LEVEL_HIGH>,
				<AIC_IRQ 422 IRQ_TYPE_LEVEL_HIGH>;
			interrupt-names = "send-empty", "send-not-empty",
				"recv-empty", "recv-not-empty";
			#mbox-cells = <0>;
			status = "disabled";
		};

		aop_dart: iommu@374818000 {
			compatible = "apple,t6030-dart", "apple,t8110-dart";
			reg = <0x3 0x74818000 0x0 0x4000>;
			#iommu-cells = <1>;
			interrupt-parent = <&aic>;
			interrupts = <AIC_IRQ 439 IRQ_TYPE_LEVEL_HIGH>;
			status = "disabled";
		};

		aop_admac: dma-controller@374980000 {
			compatible = "apple,t6030-admac", "apple,t8122-admac";
			reg = <0x3 0x74980000 0x0 0x34000>;
			#dma-cells = <1>;
			dma-channels = <16>;
			interrupts-extended = <0>,
					      <0>,
					      <&aic AIC_IRQ 460 IRQ_TYPE_LEVEL_HIGH>,
					      <0>;
			iommus = <&aop_dart 10>;
			status = "disabled";
		};

		aop: aop@374c00000 {
			compatible = "apple,t6030-aop", "apple,t6020-aop";
			reg = <0x3 0x74c00000 0x0 0x1e0000>,
			      <0x3 0x74400000 0x0 0x6c000>;
			mboxes = <&aop_mbox>;
			mbox-names = "mbox";
			iommus = <&aop_dart 0>;

			status = "disabled";

			aop_audio: audio {
				compatible = "apple,t6030-aop-audio";
				dmas = <&aop_admac 1>;
				dma-names = "dma";
			};

			aop_als: als {
				compatible = "apple,t6030-aop-als", "apple,t6020-aop-als", "apple,aop-als";
				// intentionally empty
			};

			las {
				compatible = "apple,t6030-aop-las", "apple,t6020-aop-las", "apple,aop-las";
			};
		};

		pinctrl_aop: pinctrl@374824000 {
			compatible = "apple,t6030-pinctrl", "apple,t8103-pinctrl";
			reg = <0x3 0x74824000 0x0 0x4000>;

			interrupt-parent = <&aic>;
			interrupts = <AIC_IRQ 394 IRQ_TYPE_LEVEL_HIGH>,
				     <AIC_IRQ 395 IRQ_TYPE_LEVEL_HIGH>,
				     <AIC_IRQ 396 IRQ_TYPE_LEVEL_HIGH>,
				     <AIC_IRQ 397 IRQ_TYPE_LEVEL_HIGH>,
				     <AIC_IRQ 398 IRQ_TYPE_LEVEL_HIGH>,
				     <AIC_IRQ 399 IRQ_TYPE_LEVEL_HIGH>,
				     <AIC_IRQ 400 IRQ_TYPE_LEVEL_HIGH>;

			clocks = <&clkref>;

			gpio-controller;
			#gpio-cells = <2>;
			gpio-ranges = <&pinctrl_aop 0 0 54>;
			apple,npins = <54>;

			interrupt-controller;
			#interrupt-cells = <2>;

			acio0_pins: acio0-pins {
				pinmux = <APPLE_PINMUX(25, 1)>;
			};

			acio1_pins: acio1-pins {
				pinmux = <APPLE_PINMUX(27, 1)>;
			};

			acio2_pins: acio2-pins {
				pinmux = <APPLE_PINMUX(29, 1)>;
			};
		};

		mtp: mtp@37a400000 {
			compatible = "apple,t6030-mtp", "apple,t6030-rtk-helper-asc4", "apple,mtp", "apple,rtk-helper-asc4";
			reg = <0x3 0x7a400000 0x0 0x4000>,
				<0x3 0x7ac00000 0x0 0x100000>;
			reg-names = "asc", "sram";

			mboxes = <&mtp_mbox>;
			iommus = <&mtp_dart 1>;
			#helper-cells = <0>;

			status = "disabled";
		};

		mtp_mbox: mbox@37a408000 {
			compatible = "apple,t6030-asc-mailbox", "apple,asc-mailbox-v4";
			reg = <0x3 0x7a408000 0x0 0x4000>;

			interrupt-parent = <&aic>;
			interrupts = <AIC_IRQ 953 IRQ_TYPE_LEVEL_HIGH>,
				<AIC_IRQ 954 IRQ_TYPE_LEVEL_HIGH>,
				<AIC_IRQ 955 IRQ_TYPE_LEVEL_HIGH>,
				<AIC_IRQ 956 IRQ_TYPE_LEVEL_HIGH>;
			interrupt-names = "send-empty", "send-not-empty",
				"recv-empty", "recv-not-empty";
			#mbox-cells = <0>;
			status = "disabled";
		};

		mtp_dart: iommu@37a808000 {
			compatible = "apple,t6030-dart", "apple,t8110-dart";
			reg = <0x3 0x7a808000 0x0 0x4000>;

			interrupt-parent = <&aic>;
			interrupts = <AIC_IRQ 937 IRQ_TYPE_LEVEL_HIGH>;

			#iommu-cells = <1>;

			status = "disabled";
		};

		mtp_dockchannel: fifo@37ab30000 {
			compatible = "apple,t6030-dockchannel", "apple,dockchannel";
			reg = <0x3 0x7ab14000 0x0 0x4000>;
			reg-names = "irq";
			interrupt-parent = <&aic>;
			interrupts = <AIC_IRQ 939 IRQ_TYPE_LEVEL_HIGH>;

			ranges = <0 0x3 0x7ab28000 0x20000>;
			nonposted-mmio;
			#address-cells = <1>;
			#size-cells = <1>;

			interrupt-controller;
			#interrupt-cells = <2>;

			status = "disabled";

			mtp_hid: input@0 {
				compatible = "apple,dockchannel-hid";
				reg = <0x0000 0x4000>,
				      <0x4000 0x4000>,
				      <0x8000 0x4000>,
				      <0xc000 0x4000>;
				reg-names = "rmt-config", "rmt-data", "config", "data";

				iommus = <&mtp_dart 1>;

				interrupt-parent = <&mtp_dockchannel>;
				interrupts = <2 IRQ_TYPE_LEVEL_HIGH>,
					<3 IRQ_TYPE_LEVEL_HIGH>;
				interrupt-names = "tx", "rx";

				apple,fifo-size = <0x800>;
				apple,helper-cpu = <&mtp>;
			};
		};

		ans_mbox: mbox@389408000 {
			compatible = "apple,t6030-asc-mailbox", "apple,asc-mailbox-v4";
			reg = <0x3 0x89408000 0x0 0x4000>;

			interrupt-parent = <&aic>;
			interrupts = <AIC_IRQ 839 IRQ_TYPE_LEVEL_HIGH>,
				<AIC_IRQ 840 IRQ_TYPE_LEVEL_HIGH>,
				<AIC_IRQ 841 IRQ_TYPE_LEVEL_HIGH>,
				<AIC_IRQ 842 IRQ_TYPE_LEVEL_HIGH>;
			interrupt-names = "send-empty", "send-not-empty",
					  "recv-empty", "recv-not-empty";

			#mbox-cells = <0>;
			#if defined(APPLE_USE_PMP)
			power-domains = <&pmp_report_ans>;
			#else
			power-domains = <&ps_ans>;
			#endif
		};

		sart: sart@38dc50000 {
			compatible = "apple,t6030-sart", "apple,t6000-sart";
			reg = <0x3 0x8dc50000 0x0 0xc000>;
			#if defined(APPLE_USE_PMP)
			power-domains = <&pmp_report_ans>;
			#else
			power-domains = <&ps_ans>;
			#endif
		};

		nvme: nvme@38dcc0000 {
			compatible = "apple,t6030-nvme-ans3", "apple,t8103-nvme-ans2";
			reg = <0x3 0x8dcc0000 0x0 0x60000>,
			      <0x3 0x89400000 0x0 0x4000>;
			reg-names = "nvme", "ans";

			interrupt-parent = <&aic>;
			interrupts = <AIC_IRQ 851 IRQ_TYPE_LEVEL_HIGH>;

			mboxes = <&ans_mbox>;
			apple,sart = <&sart>;

			#if defined(APPLE_USE_PMP)
			power-domains = <&pmp_report_ans>, <&ps_apcie_sys_st>;
			#else
			power-domains = <&ps_ans>, <&ps_apcie_sys_st>;
			#endif
			power-domain-names = "ans", "apcie0";
			resets = <&ps_ans>;
		};

		pcie0: pcie@580000000 {
			compatible = "apple,t6030-pcie", "apple,t6020-pcie";
			device_type = "pci";

			reg = <0x5 0x80000000 0x0 0x1000000>,	/* config */
				<0x5 0x91000000 0x0 0x4000>,	/* rc */
				<0x5 0x94008000 0x0 0x4000>,	/* port0 */
				<0x5 0x95008000 0x0 0x4000>,	/* port1 */
				<0x5 0x96008000 0x0 0x4000>,	/* port2 */
				<0x5 0x97008000 0x0 0x4000>,	/* port3 */
				<0x5 0x9e020000 0x0 0x4000>,	/* phy0 */
				<0x5 0x9e024000 0x0 0x4000>,	/* phy1 */
				<0x5 0x9e028000 0x0 0x4000>,	/* phy2 */
				<0x5 0x9e02c000 0x0 0x4000>,	/* phy3 */
				/*
				 * What a deep sleep takes and its wake sets up again, as
				 * the J516s ADT's /arm-io/apcie reg[4], [5], [6],
				 * [2] + 0x4000, [2] + 0x8000 and [3]
				 */
				<0x5 0x9c000000 0x0 0x8000>,	/* axi2af */
				<0x5 0x9e08a200 0x0 0x4000>,	/* cio3pll */
				<0x5 0x9e088000 0x0 0x4000>,	/* clkgen */
				<0x5 0x9e008000 0x0 0x4000>,	/* phy-common */
				<0x5 0x9e00c000 0x0 0x4000>,	/* phy-shared */
				<0x5 0x9e040000 0x0 0x40000>;	/* phy-ip */
			reg-names = "config", "rc",
				    "port0", "port1", "port2", "port3",
				    "phy0", "phy1", "phy2", "phy3",
				    "axi2af", "cio3pll", "clkgen",
				    "phy-common", "phy-shared", "phy-ip";

			interrupt-parent = <&aic>;
			interrupts = <AIC_IRQ 1038 IRQ_TYPE_LEVEL_HIGH>,
				     <AIC_IRQ 1047 IRQ_TYPE_LEVEL_HIGH>,
				     <AIC_IRQ 1056 IRQ_TYPE_LEVEL_HIGH>,
				     <AIC_IRQ 1065 IRQ_TYPE_LEVEL_HIGH>;

			msi-controller;
			msi-parent = <&pcie0>;
			msi-ranges = <&aic AIC_IRQ 1342 IRQ_TYPE_EDGE_RISING 32>;

			iommu-map = <0x100 &pcie0_dart_0 1 1>,
				    <0x200 &pcie0_dart_1 1 1>,
				    <0x300 &pcie0_dart_2 1 1>,
				    <0x400 &pcie0_dart_3 1 1>;
			iommu-map-mask = <0xff00>;

			bus-range = <0 4>;
			#address-cells = <3>;
			#size-cells = <2>;
			ranges = <0x43000000 0x5 0xa0000000 0x5 0xa0000000 0x0 0x20000000>,
				 <0x02000000 0x0 0xc0000000 0x5 0xc0000000 0x0 0x40000000>;

			power-domains = <&ps_apcie_sys_gp>;
			pinctrl-0 = <&pcie_pins>;
			pinctrl-names = "default";

			port00: pci@0,0 {
				device_type = "pci";
				reg = <0x0 0x0 0x0 0x0 0x0>;
				reset-gpios = <&pinctrl_ap 167 GPIO_ACTIVE_LOW>; // perst

				#address-cells = <3>;
				#size-cells = <2>;
				ranges;

				interrupt-controller;
				#interrupt-cells = <1>;

				interrupt-map-mask = <0 0 0 7>;
				interrupt-map = <0 0 0 1 &port00 0 0 0 0>,
						<0 0 0 2 &port00 0 0 0 1>,
						<0 0 0 3 &port00 0 0 0 2>,
						<0 0 0 4 &port00 0 0 0 3>;
			};

			port01: pci@1,0 {
				device_type = "pci";
				reg = <0x800 0x0 0x0 0x0 0x0>;
				reset-gpios = <&pinctrl_ap 168 GPIO_ACTIVE_LOW>; // perst

				#address-cells = <3>;
				#size-cells = <2>;
				ranges;

				interrupt-controller;
				#interrupt-cells = <1>;

				interrupt-map-mask = <0 0 0 7>;
				interrupt-map = <0 0 0 1 &port01 0 0 0 0>,
						<0 0 0 2 &port01 0 0 0 1>,
						<0 0 0 3 &port01 0 0 0 2>,
						<0 0 0 4 &port01 0 0 0 3>;
				status = "disabled";
			};

			port02: pci@2,0 {
				device_type = "pci";
				reg = <0x1000 0x0 0x0 0x0 0x0>;
				reset-gpios = <&pinctrl_ap 169 GPIO_ACTIVE_LOW>; // perst

				#address-cells = <3>;
				#size-cells = <2>;
				ranges;

				interrupt-controller;
				#interrupt-cells = <1>;

				interrupt-map-mask = <0 0 0 7>;
				interrupt-map = <0 0 0 1 &port02 0 0 0 0>,
						<0 0 0 2 &port02 0 0 0 1>,
						<0 0 0 3 &port02 0 0 0 2>,
						<0 0 0 4 &port02 0 0 0 3>;
				status = "disabled";
			};

			port03: pci@3,0 {
				device_type = "pci";
				reg = <0x1800 0x0 0x0 0x0 0x0>;
				reset-gpios = <&pinctrl_ap 170 GPIO_ACTIVE_LOW>; // perst

				#address-cells = <3>;
				#size-cells = <2>;
				ranges;

				interrupt-controller;
				#interrupt-cells = <1>;

				interrupt-map-mask = <0 0 0 7>;
				interrupt-map = <0 0 0 1 &port03 0 0 0 0>,
						<0 0 0 2 &port03 0 0 0 1>,
						<0 0 0 3 &port03 0 0 0 2>,
						<0 0 0 4 &port03 0 0 0 3>;
				status = "disabled";
			};
		};

		pcie0_dart_0: iommu@594000000 {
			compatible = "apple,t6030-dart", "apple,t8110-dart";
			reg = <0x5 0x94000000 0x0 0x4000>;
			#iommu-cells = <1>;
			interrupt-parent = <&aic>;
			interrupts = <AIC_IRQ 1039 IRQ_TYPE_LEVEL_HIGH>;
			power-domains = <&ps_apcie_sys_gp>;
		};

		pcie0_dart_1: iommu@595000000 {
			compatible = "apple,t6030-dart", "apple,t8110-dart";
			reg = <0x5 0x95000000 0x0 0x4000>;
			#iommu-cells = <1>;
			interrupt-parent = <&aic>;
			interrupts = <AIC_IRQ 1048 IRQ_TYPE_LEVEL_HIGH>;
			power-domains = <&ps_apcie_sys_gp>;
			status = "disabled";
		};

		pcie0_dart_2: iommu@596000000 {
			compatible = "apple,t6030-dart", "apple,t8110-dart";
			reg = <0x5 0x96000000 0x0 0x4000>;
			#iommu-cells = <1>;
			interrupt-parent = <&aic>;
			interrupts = <AIC_IRQ 1057 IRQ_TYPE_LEVEL_HIGH>;
			power-domains = <&ps_apcie_sys_gp>;
			status = "disabled";
		};

		pcie0_dart_3: iommu@597000000 {
			compatible = "apple,t6030-dart", "apple,t8110-dart";
			reg = <0x5 0x97000000 0x0 0x4000>;
			#iommu-cells = <1>;
			interrupt-parent = <&aic>;
			interrupts = <AIC_IRQ 1066 IRQ_TYPE_LEVEL_HIGH>;
			power-domains = <&ps_apcie_sys_gp>;
			status = "disabled";
		};

		usb4_0_mbox: mailbox@701108000 {
			compatible = "apple,t6030-asc-mailbox",
				"apple,asc-mailbox-v4";
			reg = <0x7 0x01108000 0x0 0x4000>;
			interrupt-parent = <&aic>;
			interrupts = <AIC_IRQ 1128 IRQ_TYPE_LEVEL_HIGH>,
				<AIC_IRQ 1129 IRQ_TYPE_LEVEL_HIGH>,
				<AIC_IRQ 1130 IRQ_TYPE_LEVEL_HIGH>,
				<AIC_IRQ 1131 IRQ_TYPE_LEVEL_HIGH>;
			interrupt-names = "send-empty", "send-not-empty",
				"recv-empty", "recv-not-empty";
			#mbox-cells = <0>;
		};

		usb4_0_acio: cio@701ac0000 {
			compatible = "apple,t6030-usb4-acio", "apple,t8103-usb4-acio";
			reg = <0x7 0x01ac0000 0x0 0xc000>,
				<0x7 0x01080000 0x0 0x20000>;
			reg-names = "rc", "sram";

			mboxes = <&usb4_0_mbox>;
			resets = <&cio_reset 0>;

			power-domains = <&ps_atc0_cio>,
					<&ps_atc0_cio_pcie>,
					<&ps_atc0_cio_usb>;

			thunderbolt-switch;

			pinctrl-0 = <&acio0_pins>;
			pinctrl-names = "default";

			#address-cells = <1>;
			#size-cells = <1>;
			ranges = <0x0 0x7 0x01000000 0x1000000>;
			nonposted-mmio;

			usb4_0_dart: iommu@a80000 {
				compatible = "apple,t6030-dart", "apple,t8110-dart";
				reg = <0xa80000 0x4000>;
				interrupt-parent = <&aic>;
				interrupts = <AIC_IRQ 1126 IRQ_TYPE_LEVEL_HIGH>;
				#iommu-cells = <5>;
				power-domains = <&ps_atc0_cio>;
			};

			usb4_0_nhi: nhi@f00000 {
				reg = <0xf00000 0x100000>,
					<0xdb0000 0x30004>;
				reg-names = "nhi", "pdf";
				compatible = "apple,t6030-usb4-nhi",
					"apple,t8103-usb4-nhi";
				interrupt-parent = <&aic>;
				interrupts = <AIC_IRQ 1099 IRQ_TYPE_LEVEL_HIGH>,
					<AIC_IRQ 1100 IRQ_TYPE_LEVEL_HIGH>,
					<AIC_IRQ 1101 IRQ_TYPE_LEVEL_HIGH>,
					<AIC_IRQ 1102 IRQ_TYPE_LEVEL_HIGH>,
					<AIC_IRQ 1103 IRQ_TYPE_LEVEL_HIGH>,
					<AIC_IRQ 1104 IRQ_TYPE_LEVEL_HIGH>,
					<AIC_IRQ 1105 IRQ_TYPE_LEVEL_HIGH>,
					<AIC_IRQ 1106 IRQ_TYPE_LEVEL_HIGH>,
					<AIC_IRQ 1107 IRQ_TYPE_LEVEL_HIGH>,
					<AIC_IRQ 1108 IRQ_TYPE_LEVEL_HIGH>,
					<AIC_IRQ 1109 IRQ_TYPE_LEVEL_HIGH>,
					<AIC_IRQ 1110 IRQ_TYPE_LEVEL_HIGH>,
					<AIC_IRQ 1111 IRQ_TYPE_LEVEL_HIGH>,
					<AIC_IRQ 1112 IRQ_TYPE_LEVEL_HIGH>,
					<AIC_IRQ 1113 IRQ_TYPE_LEVEL_HIGH>,
					<AIC_IRQ 1114 IRQ_TYPE_LEVEL_HIGH>,
					<AIC_IRQ 1115 IRQ_TYPE_LEVEL_HIGH>,
					<AIC_IRQ 1116 IRQ_TYPE_LEVEL_HIGH>,
					<AIC_IRQ 1117 IRQ_TYPE_LEVEL_HIGH>,
					<AIC_IRQ 1118 IRQ_TYPE_LEVEL_HIGH>,
					<AIC_IRQ 1119 IRQ_TYPE_LEVEL_HIGH>,
					<AIC_IRQ 1120 IRQ_TYPE_LEVEL_HIGH>,
					<AIC_IRQ 1121 IRQ_TYPE_LEVEL_HIGH>,
					<AIC_IRQ 1122 IRQ_TYPE_LEVEL_HIGH>;
				interrupt-names =
					"txring0", "txring1", "txring2",
					"txring3", "txring4", "txring5",
					"txring6", "txring7", "txring8",
					"txring9", "txring10", "txring11",
					"rxring0", "rxring1", "rxring2",
					"rxring3", "rxring4", "rxring5",
					"rxring6", "rxring7", "rxring8",
					"rxring9", "rxring10", "rxring11";
				iommus = <&usb4_0_dart 0 0x100 0x0 0x10 0x0>,
					<&usb4_0_dart 1 0x100 0x0 0x10 0x0>,
					<&usb4_0_dart 2 0x100 0x0 0x10 0x0>,
					<&usb4_0_dart 3 0x100 0x0 0x10 0x0>,
					<&usb4_0_dart 4 0x100 0x0 0x10 0x0>,
					<&usb4_0_dart 5 0x100 0x0 0x10 0x0>,
					<&usb4_0_dart 6 0x100 0x0 0x10 0x0>,
					<&usb4_0_dart 7 0x100 0x0 0x10 0x0>,
					<&usb4_0_dart 8 0x100 0x0 0x10 0x0>,
					<&usb4_0_dart 9 0x100 0x0 0x10 0x0>,
					<&usb4_0_dart 10 0x100 0x0 0x10 0x0>,
					<&usb4_0_dart 11 0x100 0x0 0x10 0x0>,
					<&usb4_0_dart 16 0x100 0x0 0x10 0x0>,
					<&usb4_0_dart 17 0x100 0x0 0x10 0x0>,
					<&usb4_0_dart 18 0x100 0x0 0x10 0x0>,
					<&usb4_0_dart 19 0x100 0x0 0x10 0x0>,
					<&usb4_0_dart 20 0x100 0x0 0x10 0x0>,
					<&usb4_0_dart 21 0x100 0x0 0x10 0x0>,
					<&usb4_0_dart 22 0x100 0x0 0x10 0x0>,
					<&usb4_0_dart 23 0x100 0x0 0x10 0x0>,
					<&usb4_0_dart 24 0x100 0x0 0x10 0x0>,
					<&usb4_0_dart 25 0x100 0x0 0x10 0x0>,
					<&usb4_0_dart 26 0x100 0x0 0x10 0x0>,
					<&usb4_0_dart 27 0x100 0x0 0x10 0x0>;
				/* To be filled by the loader */
				apple,thunderbolt-drom = [00];
			};
		};

		dwc3_0: usb@702280000 {
			compatible = "apple,t6030-dwc3", "apple,t8103-dwc3";
			reg = <0x7 0x02280000 0x0 0xcd00>, <0x7 0x0228cd00 0x0 0x3200>;
			reg-names = "dwc3-core", "dwc3-apple";
			interrupt-parent = <&aic>;
			interrupts = <AIC_IRQ 1087 IRQ_TYPE_LEVEL_HIGH>;
			dr_mode = "otg";
			usb-role-switch;
			role-switch-default-mode = "host";
			iommus = <&dwc3_0_dart_0 0>,
				<&dwc3_0_dart_1 1>;
			power-domains = <&ps_atc0_usb>;
			resets = <&atcphy0>;
			phys = <&atcphy0 PHY_TYPE_USB2>, <&atcphy0 PHY_TYPE_USB3>;
			phy-names = "usb2-phy", "usb3-phy";
		};

		dwc3_0_dart_0: iommu@702f00000 {
			compatible = "apple,t6030-dart", "apple,t8110-dart";
			reg = <0x7 0x02f00000 0x0 0x4000>;
			interrupt-parent = <&aic>;
			interrupts = <AIC_IRQ 1091 IRQ_TYPE_LEVEL_HIGH>;
			power-domains = <&ps_atc0_usb>;
			#iommu-cells = <1>;
		};

		dwc3_0_dart_1: iommu@702f80000 {
			compatible = "apple,t6030-dart", "apple,t8110-dart";
			reg = <0x7 0x02f80000 0x0 0x4000>;
			interrupt-parent = <&aic>;
			interrupts = <AIC_IRQ 1091 IRQ_TYPE_LEVEL_HIGH>;
			power-domains = <&ps_atc0_usb>;
			#iommu-cells = <1>;
		};

		atcphy0: phy@703000000 {
			compatible = "apple,t6030-atcphy", "apple,t8122-atcphy";
			reg = <0x7 0x03000000 0x0 0x4c000>,
				<0x7 0x03050000 0x0 0x8000>,
				<0x7 0x00000000 0x0 0x8000>,
				<0x7 0x02a90000 0x0 0x4000>,
				<0x7 0x02a84000 0x0 0x4000>;
			reg-names = "core", "lpdptx", "axi2af", "usb2phy",
				"pipehandler";

			#phy-cells = <1>;
			#reset-cells = <0>;

			orientation-switch;
			mode-switch;
			power-domains = <&ps_atc0_usb>;
		};

		usb4_1_mbox: mailbox@b01108000 {
			compatible = "apple,t6030-asc-mailbox",
				"apple,asc-mailbox-v4";
			reg = <0xb 0x01108000 0x0 0x4000>;
			interrupt-parent = <&aic>;
			interrupts = <AIC_IRQ 1186 IRQ_TYPE_LEVEL_HIGH>,
				<AIC_IRQ 1187 IRQ_TYPE_LEVEL_HIGH>,
				<AIC_IRQ 1188 IRQ_TYPE_LEVEL_HIGH>,
				<AIC_IRQ 1189 IRQ_TYPE_LEVEL_HIGH>;
			interrupt-names = "send-empty", "send-not-empty",
				"recv-empty", "recv-not-empty";
			#mbox-cells = <0>;
		};

		usb4_1_acio: cio@b01ac0000 {
			compatible = "apple,t6030-usb4-acio", "apple,t8103-usb4-acio";
			reg = <0xb 0x01ac0000 0x0 0xc000>,
				<0xb 0x01080000 0x0 0x20000>;
			reg-names = "rc", "sram";

			mboxes = <&usb4_1_mbox>;
			resets = <&cio_reset 1>;

			power-domains = <&ps_atc1_cio>,
					<&ps_atc1_cio_pcie>,
					<&ps_atc1_cio_usb>;

			thunderbolt-switch;

			pinctrl-0 = <&acio1_pins>;
			pinctrl-names = "default";

			#address-cells = <1>;
			#size-cells = <1>;
			ranges = <0x0 0xb 0x01000000 0x1000000>;
			nonposted-mmio;

			usb4_1_dart: iommu@a80000 {
				compatible = "apple,t6030-dart", "apple,t8110-dart";
				reg = <0xa80000 0x4000>;
				interrupt-parent = <&aic>;
				interrupts = <AIC_IRQ 1184 IRQ_TYPE_LEVEL_HIGH>;
				#iommu-cells = <5>;
				power-domains = <&ps_atc1_cio>;
			};

			usb4_1_nhi: nhi@f00000 {
				reg = <0xf00000 0x100000>,
					<0xdb0000 0x30004>;
				reg-names = "nhi", "pdf";
				compatible = "apple,t6030-usb4-nhi",
					"apple,t8103-usb4-nhi";
				interrupt-parent = <&aic>;
				interrupts = <AIC_IRQ 1157 IRQ_TYPE_LEVEL_HIGH>,
					<AIC_IRQ 1158 IRQ_TYPE_LEVEL_HIGH>,
					<AIC_IRQ 1159 IRQ_TYPE_LEVEL_HIGH>,
					<AIC_IRQ 1160 IRQ_TYPE_LEVEL_HIGH>,
					<AIC_IRQ 1161 IRQ_TYPE_LEVEL_HIGH>,
					<AIC_IRQ 1162 IRQ_TYPE_LEVEL_HIGH>,
					<AIC_IRQ 1163 IRQ_TYPE_LEVEL_HIGH>,
					<AIC_IRQ 1164 IRQ_TYPE_LEVEL_HIGH>,
					<AIC_IRQ 1165 IRQ_TYPE_LEVEL_HIGH>,
					<AIC_IRQ 1166 IRQ_TYPE_LEVEL_HIGH>,
					<AIC_IRQ 1167 IRQ_TYPE_LEVEL_HIGH>,
					<AIC_IRQ 1168 IRQ_TYPE_LEVEL_HIGH>,
					<AIC_IRQ 1169 IRQ_TYPE_LEVEL_HIGH>,
					<AIC_IRQ 1170 IRQ_TYPE_LEVEL_HIGH>,
					<AIC_IRQ 1171 IRQ_TYPE_LEVEL_HIGH>,
					<AIC_IRQ 1172 IRQ_TYPE_LEVEL_HIGH>,
					<AIC_IRQ 1173 IRQ_TYPE_LEVEL_HIGH>,
					<AIC_IRQ 1174 IRQ_TYPE_LEVEL_HIGH>,
					<AIC_IRQ 1175 IRQ_TYPE_LEVEL_HIGH>,
					<AIC_IRQ 1176 IRQ_TYPE_LEVEL_HIGH>,
					<AIC_IRQ 1177 IRQ_TYPE_LEVEL_HIGH>,
					<AIC_IRQ 1178 IRQ_TYPE_LEVEL_HIGH>,
					<AIC_IRQ 1179 IRQ_TYPE_LEVEL_HIGH>,
					<AIC_IRQ 1180 IRQ_TYPE_LEVEL_HIGH>;
				interrupt-names =
					"txring0", "txring1", "txring2",
					"txring3", "txring4", "txring5",
					"txring6", "txring7", "txring8",
					"txring9", "txring10", "txring11",
					"rxring0", "rxring1", "rxring2",
					"rxring3", "rxring4", "rxring5",
					"rxring6", "rxring7", "rxring8",
					"rxring9", "rxring10", "rxring11";
				iommus = <&usb4_1_dart 0 0x100 0x0 0x10 0x0>,
					<&usb4_1_dart 1 0x100 0x0 0x10 0x0>,
					<&usb4_1_dart 2 0x100 0x0 0x10 0x0>,
					<&usb4_1_dart 3 0x100 0x0 0x10 0x0>,
					<&usb4_1_dart 4 0x100 0x0 0x10 0x0>,
					<&usb4_1_dart 5 0x100 0x0 0x10 0x0>,
					<&usb4_1_dart 6 0x100 0x0 0x10 0x0>,
					<&usb4_1_dart 7 0x100 0x0 0x10 0x0>,
					<&usb4_1_dart 8 0x100 0x0 0x10 0x0>,
					<&usb4_1_dart 9 0x100 0x0 0x10 0x0>,
					<&usb4_1_dart 10 0x100 0x0 0x10 0x0>,
					<&usb4_1_dart 11 0x100 0x0 0x10 0x0>,
					<&usb4_1_dart 16 0x100 0x0 0x10 0x0>,
					<&usb4_1_dart 17 0x100 0x0 0x10 0x0>,
					<&usb4_1_dart 18 0x100 0x0 0x10 0x0>,
					<&usb4_1_dart 19 0x100 0x0 0x10 0x0>,
					<&usb4_1_dart 20 0x100 0x0 0x10 0x0>,
					<&usb4_1_dart 21 0x100 0x0 0x10 0x0>,
					<&usb4_1_dart 22 0x100 0x0 0x10 0x0>,
					<&usb4_1_dart 23 0x100 0x0 0x10 0x0>,
					<&usb4_1_dart 24 0x100 0x0 0x10 0x0>,
					<&usb4_1_dart 25 0x100 0x0 0x10 0x0>,
					<&usb4_1_dart 26 0x100 0x0 0x10 0x0>,
					<&usb4_1_dart 27 0x100 0x0 0x10 0x0>;
				/* To be filled by the loader */
				apple,thunderbolt-drom = [00];
			};
		};

		atcphy0_xbar: mux@70304c000 {
			compatible = "apple,t6030-display-crossbar",
				     "apple,t6020-display-crossbar";
			reg = <0x7 0x0304c000 0x0 0x4000>;
			#mux-control-cells = <1>;
			power-domains = <&ps_atc0_usb>;
		};

		dwc3_1: usb@b02280000 {
			compatible = "apple,t6030-dwc3", "apple,t8103-dwc3";
			reg = <0xb 0x02280000 0x0 0xcd00>, <0xb 0x0228cd00 0x0 0x3200>;
			reg-names = "dwc3-core", "dwc3-apple";
			interrupt-parent = <&aic>;
			interrupts = <AIC_IRQ 1145 IRQ_TYPE_LEVEL_HIGH>;
			dr_mode = "otg";
			usb-role-switch;
			role-switch-default-mode = "host";
			iommus = <&dwc3_1_dart_0 0>,
				<&dwc3_1_dart_1 1>;
			power-domains = <&ps_atc1_usb>;
			resets = <&atcphy1>;
			phys = <&atcphy1 PHY_TYPE_USB2>, <&atcphy1 PHY_TYPE_USB3>;
			phy-names = "usb2-phy", "usb3-phy";
		};

		dwc3_1_dart_0: iommu@b02f00000 {
			compatible = "apple,t6030-dart", "apple,t8110-dart";
			reg = <0xb 0x02f00000 0x0 0x4000>;
			interrupt-parent = <&aic>;
			interrupts = <AIC_IRQ 1149 IRQ_TYPE_LEVEL_HIGH>;
			power-domains = <&ps_atc1_usb>;
			#iommu-cells = <1>;
		};

		dwc3_1_dart_1: iommu@b02f80000 {
			compatible = "apple,t6030-dart", "apple,t8110-dart";
			reg = <0xb 0x02f80000 0x0 0x4000>;
			interrupt-parent = <&aic>;
			interrupts = <AIC_IRQ 1149 IRQ_TYPE_LEVEL_HIGH>;
			power-domains = <&ps_atc1_usb>;
			#iommu-cells = <1>;
		};

		atcphy1: phy@b03000000 {
			compatible = "apple,t6030-atcphy", "apple,t8122-atcphy";
			reg = <0xb 0x03000000 0x0 0x4c000>,
				<0xb 0x03050000 0x0 0x8000>,
				<0xb 0x00000000 0x0 0x8000>,
				<0xb 0x02a90000 0x0 0x4000>,
				<0xb 0x02a84000 0x0 0x4000>;
			reg-names = "core", "lpdptx", "axi2af", "usb2phy",
				"pipehandler";

			#phy-cells = <1>;
			#reset-cells = <0>;

			orientation-switch;
			mode-switch;
			power-domains = <&ps_atc1_usb>;
		};

		usb4_2_mbox: mailbox@f01108000 {
			compatible = "apple,t6030-asc-mailbox",
				"apple,asc-mailbox-v4";
			reg = <0xf 0x01108000 0x0 0x4000>;
			interrupt-parent = <&aic>;
			interrupts = <AIC_IRQ 1244 IRQ_TYPE_LEVEL_HIGH>,
				<AIC_IRQ 1245 IRQ_TYPE_LEVEL_HIGH>,
				<AIC_IRQ 1246 IRQ_TYPE_LEVEL_HIGH>,
				<AIC_IRQ 1247 IRQ_TYPE_LEVEL_HIGH>;
			interrupt-names = "send-empty", "send-not-empty",
				"recv-empty", "recv-not-empty";
			#mbox-cells = <0>;
		};

		usb4_2_acio: cio@f01ac0000 {
			compatible = "apple,t6030-usb4-acio", "apple,t8103-usb4-acio";
			reg = <0xf 0x01ac0000 0x0 0xc000>,
				<0xf 0x01080000 0x0 0x20000>;
			reg-names = "rc", "sram";

			mboxes = <&usb4_2_mbox>;
			resets = <&cio_reset 2>;

			power-domains = <&ps_atc2_cio>,
					<&ps_atc2_cio_pcie>,
					<&ps_atc2_cio_usb>;

			thunderbolt-switch;

			pinctrl-0 = <&acio2_pins>;
			pinctrl-names = "default";

			#address-cells = <1>;
			#size-cells = <1>;
			ranges = <0x0 0xf 0x01000000 0x1000000>;
			nonposted-mmio;

			usb4_2_dart: iommu@a80000 {
				compatible = "apple,t6030-dart", "apple,t8110-dart";
				reg = <0xa80000 0x4000>;
				interrupt-parent = <&aic>;
				interrupts = <AIC_IRQ 1242 IRQ_TYPE_LEVEL_HIGH>;
				#iommu-cells = <5>;
				power-domains = <&ps_atc2_cio>;
			};

			usb4_2_nhi: nhi@f00000 {
				reg = <0xf00000 0x100000>,
					<0xdb0000 0x30004>;
				reg-names = "nhi", "pdf";
				compatible = "apple,t6030-usb4-nhi",
					"apple,t8103-usb4-nhi";
				interrupt-parent = <&aic>;
				interrupts = <AIC_IRQ 1215 IRQ_TYPE_LEVEL_HIGH>,
					<AIC_IRQ 1216 IRQ_TYPE_LEVEL_HIGH>,
					<AIC_IRQ 1217 IRQ_TYPE_LEVEL_HIGH>,
					<AIC_IRQ 1218 IRQ_TYPE_LEVEL_HIGH>,
					<AIC_IRQ 1219 IRQ_TYPE_LEVEL_HIGH>,
					<AIC_IRQ 1220 IRQ_TYPE_LEVEL_HIGH>,
					<AIC_IRQ 1221 IRQ_TYPE_LEVEL_HIGH>,
					<AIC_IRQ 1222 IRQ_TYPE_LEVEL_HIGH>,
					<AIC_IRQ 1223 IRQ_TYPE_LEVEL_HIGH>,
					<AIC_IRQ 1224 IRQ_TYPE_LEVEL_HIGH>,
					<AIC_IRQ 1225 IRQ_TYPE_LEVEL_HIGH>,
					<AIC_IRQ 1226 IRQ_TYPE_LEVEL_HIGH>,
					<AIC_IRQ 1227 IRQ_TYPE_LEVEL_HIGH>,
					<AIC_IRQ 1228 IRQ_TYPE_LEVEL_HIGH>,
					<AIC_IRQ 1229 IRQ_TYPE_LEVEL_HIGH>,
					<AIC_IRQ 1230 IRQ_TYPE_LEVEL_HIGH>,
					<AIC_IRQ 1231 IRQ_TYPE_LEVEL_HIGH>,
					<AIC_IRQ 1232 IRQ_TYPE_LEVEL_HIGH>,
					<AIC_IRQ 1233 IRQ_TYPE_LEVEL_HIGH>,
					<AIC_IRQ 1234 IRQ_TYPE_LEVEL_HIGH>,
					<AIC_IRQ 1235 IRQ_TYPE_LEVEL_HIGH>,
					<AIC_IRQ 1236 IRQ_TYPE_LEVEL_HIGH>,
					<AIC_IRQ 1237 IRQ_TYPE_LEVEL_HIGH>,
					<AIC_IRQ 1238 IRQ_TYPE_LEVEL_HIGH>;
				interrupt-names =
					"txring0", "txring1", "txring2",
					"txring3", "txring4", "txring5",
					"txring6", "txring7", "txring8",
					"txring9", "txring10", "txring11",
					"rxring0", "rxring1", "rxring2",
					"rxring3", "rxring4", "rxring5",
					"rxring6", "rxring7", "rxring8",
					"rxring9", "rxring10", "rxring11";
				iommus = <&usb4_2_dart 0 0x100 0x0 0x10 0x0>,
					<&usb4_2_dart 1 0x100 0x0 0x10 0x0>,
					<&usb4_2_dart 2 0x100 0x0 0x10 0x0>,
					<&usb4_2_dart 3 0x100 0x0 0x10 0x0>,
					<&usb4_2_dart 4 0x100 0x0 0x10 0x0>,
					<&usb4_2_dart 5 0x100 0x0 0x10 0x0>,
					<&usb4_2_dart 6 0x100 0x0 0x10 0x0>,
					<&usb4_2_dart 7 0x100 0x0 0x10 0x0>,
					<&usb4_2_dart 8 0x100 0x0 0x10 0x0>,
					<&usb4_2_dart 9 0x100 0x0 0x10 0x0>,
					<&usb4_2_dart 10 0x100 0x0 0x10 0x0>,
					<&usb4_2_dart 11 0x100 0x0 0x10 0x0>,
					<&usb4_2_dart 16 0x100 0x0 0x10 0x0>,
					<&usb4_2_dart 17 0x100 0x0 0x10 0x0>,
					<&usb4_2_dart 18 0x100 0x0 0x10 0x0>,
					<&usb4_2_dart 19 0x100 0x0 0x10 0x0>,
					<&usb4_2_dart 20 0x100 0x0 0x10 0x0>,
					<&usb4_2_dart 21 0x100 0x0 0x10 0x0>,
					<&usb4_2_dart 22 0x100 0x0 0x10 0x0>,
					<&usb4_2_dart 23 0x100 0x0 0x10 0x0>,
					<&usb4_2_dart 24 0x100 0x0 0x10 0x0>,
					<&usb4_2_dart 25 0x100 0x0 0x10 0x0>,
					<&usb4_2_dart 26 0x100 0x0 0x10 0x0>,
					<&usb4_2_dart 27 0x100 0x0 0x10 0x0>;
				/* To be filled by the loader */
				apple,thunderbolt-drom = [00];
			};
		};

		atcphy1_xbar: mux@b0304c000 {
			compatible = "apple,t6030-display-crossbar",
				     "apple,t6020-display-crossbar";
			reg = <0xb 0x0304c000 0x0 0x4000>;
			#mux-control-cells = <1>;
			power-domains = <&ps_atc1_usb>;
		};

		dwc3_2: usb@f02280000 {
			compatible = "apple,t6030-dwc3", "apple,t8103-dwc3";
			reg = <0xf 0x02280000 0x0 0xcd00>, <0xf 0x0228cd00 0x0 0x3200>;
			reg-names = "dwc3-core", "dwc3-apple";
			interrupt-parent = <&aic>;
			interrupts = <AIC_IRQ 1203 IRQ_TYPE_LEVEL_HIGH>;
			dr_mode = "otg";
			usb-role-switch;
			role-switch-default-mode = "host";
			iommus = <&dwc3_2_dart_0 0>,
				<&dwc3_2_dart_1 1>;
			power-domains = <&ps_atc2_usb>;
			resets = <&atcphy2>;
			phys = <&atcphy2 PHY_TYPE_USB2>, <&atcphy2 PHY_TYPE_USB3>;
			phy-names = "usb2-phy", "usb3-phy";
		};

		dwc3_2_dart_0: iommu@f02f00000 {
			compatible = "apple,t6030-dart", "apple,t8110-dart";
			reg = <0xf 0x02f00000 0x0 0x4000>;
			interrupt-parent = <&aic>;
			interrupts = <AIC_IRQ 1207 IRQ_TYPE_LEVEL_HIGH>;
			power-domains = <&ps_atc2_usb>;
			#iommu-cells = <1>;
		};

		dwc3_2_dart_1: iommu@f02f80000 {
			compatible = "apple,t6030-dart", "apple,t8110-dart";
			reg = <0xf 0x02f80000 0x0 0x4000>;
			interrupt-parent = <&aic>;
			interrupts = <AIC_IRQ 1207 IRQ_TYPE_LEVEL_HIGH>;
			power-domains = <&ps_atc2_usb>;
			#iommu-cells = <1>;
		};

		atcphy2: phy@f03000000 {
			compatible = "apple,t6030-atcphy", "apple,t8122-atcphy";
			reg = <0xf 0x03000000 0x0 0x4c000>,
				<0xf 0x03050000 0x0 0x8000>,
				<0xf 0x00000000 0x0 0x8000>,
				<0xf 0x02a90000 0x0 0x4000>,
				<0xf 0x02a84000 0x0 0x4000>;
			reg-names = "core", "lpdptx", "axi2af", "usb2phy",
				"pipehandler";

			#phy-cells = <1>;
			#reset-cells = <0>;

			orientation-switch;
			mode-switch;
			power-domains = <&ps_atc2_usb>;
		};

		atcphy2_xbar: mux@f0304c000 {
			compatible = "apple,t6030-display-crossbar",
				     "apple,t6020-display-crossbar";
			reg = <0xf 0x0304c000 0x0 0x4000>;
			#mux-control-cells = <1>;
			power-domains = <&ps_atc2_usb>;
		};

		/* No USB-C port: a DisplayPort-only PHY for HDMI (core window only). */
		atcphy3: phy@1303000000 {
			compatible = "apple,t6030-atcphy", "apple,t8122-atcphy";
			reg = <0x13 0x03000000 0x0 0x4c000>;
			reg-names = "core";

			#phy-cells = <1>;
			#reset-cells = <0>;

			orientation-switch;
			mode-switch;
			power-domains = <&ps_atc3_common>;
			status = "disabled";
		};

		atcphy3_xbar: mux@130304c000 {
			compatible = "apple,t6030-display-crossbar",
				     "apple,t6020-display-crossbar";
			reg = <0x13 0x0304c000 0x0 0x4000>;
			#mux-control-cells = <1>;
			power-domains = <&ps_atc3_usb>;
			status = "disabled";
		};

	};
};

#include "t6030-pmgr.dtsi"
#include "t6030-gpu.dtsi"
#include "t6030-usb4.dtsi"
#include "t6030-dcp.dtsi"

#include "t6030-peripherals.dtsi"

#include "t6030-peripheral-buses.dtsi"

#include "t6030-coprocessors.dtsi"

#include "t6030-misc-interfaces.dtsi"

&smc_hwmon {
	/* Not yet checked on hardware; absent firmware keys are skipped. */
	apple,soc-die-keys = "Tf04", "Tf09", "Tf0A", "Tf0B", "Tf0D",
			     "Tf0E", "Tf14", "Tf18", "Tf19", "Tf1A",
			     "Tf24", "Tf25", "Tf2A", "Tf2B";
	apple,thermal-pressure-key = "mTPL";
};
